VERSION ""

NS_ :

BS_:

BU_: ZD VCU TPMS RESERVED_FRAMES RCM RAC PCU PAS ESP DiagnosticTester CHG CDCM BMS ABS

BO_ 1091 VCU_Stored_SC_Errors: 8 VCU
 SG_ VCUStoredBeltWarningLightSC : 13|1@0+ (1,0) [0|1] "" Vector__XXX
 SG_ VCUStoredLowSOCSC : 0|1@0+ (1,0) [0|1] "" Vector__XXX
 SG_ VCUStoredRearSeatBuckle2LightSC : 26|1@0+ (1,0) [0|1] "" Vector__XXX
 SG_ VCUStoredReverseLightSC : 9|1@0+ (1,0) [0|1] "" Vector__XXX
 SG_ VCUStoredRadioMuteSC : 33|1@0+ (1,0) [0|1] "" Vector__XXX
 SG_ VCUStoredIllumOutputSC : 21|1@0+ (1,0) [0|1] "" Vector__XXX
 SG_ VCUStoredNeutralLightSC : 8|1@0+ (1,0) [0|1] "" Vector__XXX
 SG_ VCUStoredDriveEnableLightSC : 39|1@0+ (1,0) [0|1] "" Vector__XXX
 SG_ VCUStoredOvertempLightSC : 3|1@0+ (1,0) [0|1] "" Vector__XXX
 SG_ VCUStoredIndicationBarSupplySC : 18|1@0+ (1,0) [0|1] "" Vector__XXX
 SG_ VCUStoredPowerLimitLightSC : 5|1@0+ (1,0) [0|1] "" Vector__XXX
 SG_ VCUStoredTransceiverTXSC : 20|1@0+ (1,0) [0|1] "" Vector__XXX
 SG_ VCUStoredElHazardLightSC : 2|1@0+ (1,0) [0|1] "" Vector__XXX
 SG_ VCUStoredBrakeWarningLightSC : 38|1@0+ (1,0) [0|1] "" Vector__XXX
 SG_ VCUStoredEconomyGaugeSC : 36|1@0+ (1,0) [0|1] "" Vector__XXX
 SG_ VCUStoredTransceiverSupplySC : 32|1@0+ (1,0) [0|1] "" Vector__XXX
 SG_ VCUStoredDischargeRequestSC : 25|1@0+ (1,0) [0|1] "" Vector__XXX
 SG_ VCUStoredCrashLineSC : 17|1@0+ (1,0) [0|1] "" Vector__XXX
 SG_ VCUStoredABSWarningLightSC : 4|1@0+ (1,0) [0|1] "" Vector__XXX
 SG_ VCUStoredImmoLightSC : 19|1@0+ (1,0) [0|1] "" Vector__XXX
 SG_ VCUStoredDriveLightSC : 7|1@0+ (1,0) [0|1] "" Vector__XXX
 SG_ VCUStoredAuxBattLowLightSC : 11|1@0+ (1,0) [0|1] "" Vector__XXX
 SG_ VCUStoredChargeLightSC : 31|1@0+ (1,0) [0|1] "" Vector__XXX
 SG_ VCUStoredTPMSLightSC : 12|1@0+ (1,0) [0|1] "" Vector__XXX
 SG_ VCUStoredSpeedGaugeSC : 28|1@0+ (1,0) [0|1] "" Vector__XXX
 SG_ VCUStoredEconomyLightSC : 6|1@0+ (1,0) [0|1] "" Vector__XXX
 SG_ VCUStoredOnPlugLightSC : 30|1@0+ (1,0) [0|1] "" Vector__XXX
 SG_ VCUStoredChimeLineSC : 34|1@0+ (1,0) [0|1] "" Vector__XXX
 SG_ VCUStoredESPLightSC : 15|1@0+ (1,0) [0|1] "" Vector__XXX
 SG_ VCUStoredSOCGaugeSC : 37|1@0+ (1,0) [0|1] "" Vector__XXX
 SG_ VCUStoredMILLightSC : 1|1@0+ (1,0) [0|1] "" Vector__XXX
 SG_ VCUStoredParkLightSC : 10|1@0+ (1,0) [0|1] "" Vector__XXX
 SG_ VCUStoredAirbagLightSC : 29|1@0+ (1,0) [0|1] "" Vector__XXX
 SG_ VCUStoredIgnitionSpeedSC : 16|1@0+ (1,0) [0|1] "" Vector__XXX
 SG_ VCUStoredRearSeatBuckle1LightSC : 27|1@0+ (1,0) [0|1] "" Vector__XXX

BO_ 1092 VCU_Stored_OC_Errors: 8 VCU
 SG_ VCUStoredImmoLightOC : 19|1@0+ (1,0) [0|1] "" Vector__XXX
 SG_ VCUStoredReverseLightOC : 9|1@0+ (1,0) [0|1] "" Vector__XXX
 SG_ VCUStoredDischargeRequestOC : 25|1@0+ (1,0) [0|1] "" Vector__XXX
 SG_ VCUStoredPowerLimitLightOC : 5|1@0+ (1,0) [0|1] "" Vector__XXX
 SG_ VCUStoredRearSeatBuckle1LightOC : 27|1@0+ (1,0) [0|1] "" Vector__XXX
 SG_ VCUStoredTPMSLightOC : 12|1@0+ (1,0) [0|1] "" Vector__XXX
 SG_ VCUStoredOvertempLightOC : 3|1@0+ (1,0) [0|1] "" Vector__XXX
 SG_ VCUStoredSOCGaugeOC : 37|1@0+ (1,0) [0|1] "" Vector__XXX
 SG_ VCUStoredESPLightOC : 15|1@0+ (1,0) [0|1] "" Vector__XXX
 SG_ VCUStoredCrashLineOC : 17|1@0+ (1,0) [0|1] "" Vector__XXX
 SG_ VCUStoredIndicationBarSupplyOC : 18|1@0+ (1,0) [0|1] "" Vector__XXX
 SG_ VCUStoredEconomyLightOC : 6|1@0+ (1,0) [0|1] "" Vector__XXX
 SG_ VCUStoredAirbagLightOC : 29|1@0+ (1,0) [0|1] "" Vector__XXX
 SG_ VCUStoredEconomyGaugeOC : 36|1@0+ (1,0) [0|1] "" Vector__XXX
 SG_ VCUStoredTransceiverSupplyOC : 32|1@0+ (1,0) [0|1] "" Vector__XXX
 SG_ VCUStoredDriveLightOC : 7|1@0+ (1,0) [0|1] "" Vector__XXX
 SG_ VCUStoredAuxBattLowLightOC : 11|1@0+ (1,0) [0|1] "" Vector__XXX
 SG_ VCUStoredRearSeatBuckle2LightOC : 26|1@0+ (1,0) [0|1] "" Vector__XXX
 SG_ VCUStoredIgnitionSpeedOC : 16|1@0+ (1,0) [0|1] "" Vector__XXX
 SG_ VCUStoredMILLightOC : 1|1@0+ (1,0) [0|1] "" Vector__XXX
 SG_ VCUStoredChimeLineOC : 34|1@0+ (1,0) [0|1] "" Vector__XXX
 SG_ VCUStoredDriveEnableLightOC : 39|1@0+ (1,0) [0|1] "" Vector__XXX
 SG_ VCUStoredLowSOCOC : 0|1@0+ (1,0) [0|1] "" Vector__XXX
 SG_ VCUStoredElHazardLightOC : 2|1@0+ (1,0) [0|1] "" Vector__XXX
 SG_ VCUStoredBrakeWarningLightOC : 38|1@0+ (1,0) [0|1] "" Vector__XXX
 SG_ VCUStoredIllumOutputOC : 21|1@0+ (1,0) [0|1] "" Vector__XXX
 SG_ VCUStoredABSWarningLightOC : 4|1@0+ (1,0) [0|1] "" Vector__XXX
 SG_ VCUStoredTransceiverTXOC : 20|1@0+ (1,0) [0|1] "" Vector__XXX
 SG_ VCUStoredBeltWarningLightOC : 13|1@0+ (1,0) [0|1] "" Vector__XXX
 SG_ VCUStoredSpeedGaugeOC : 28|1@0+ (1,0) [0|1] "" Vector__XXX
 SG_ VCUStoredRadioMuteOC : 33|1@0+ (1,0) [0|1] "" Vector__XXX
 SG_ VCUStoredParkLightOC : 10|1@0+ (1,0) [0|1] "" Vector__XXX
 SG_ VCUStoredNeutralLightOC : 8|1@0+ (1,0) [0|1] "" Vector__XXX
 SG_ VCUStoredChargeLightOC : 31|1@0+ (1,0) [0|1] "" Vector__XXX
 SG_ VCUStoredOnPlugLightOC : 30|1@0+ (1,0) [0|1] "" Vector__XXX

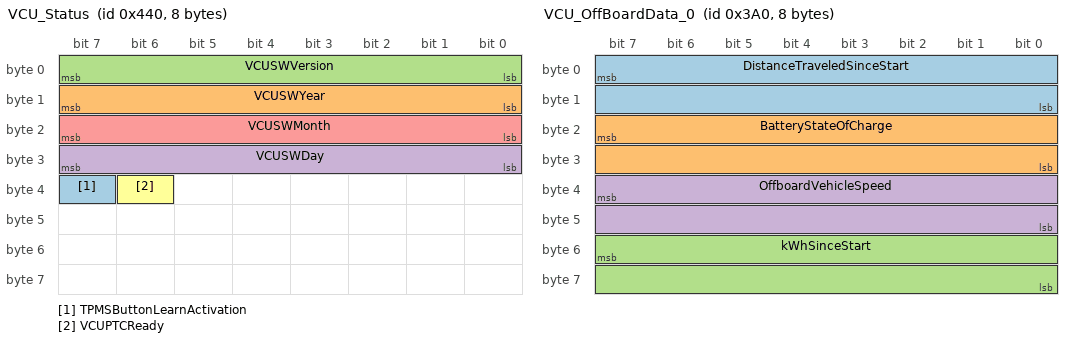
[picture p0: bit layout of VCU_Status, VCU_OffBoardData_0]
BO_ 1088 VCU_Status: 8 VCU
 SG_ TPMSButtonLearnActivation : 39|1@0+ (1,0) [0|1] "" Vector__XXX
 SG_ VCUSWYear : 15|8@0+ (1,0) [0|255] "" Vector__XXX
 SG_ VCUSWVersion : 7|8@0+ (1,0) [0|255] "" Vector__XXX
 SG_ VCUSWDay : 31|8@0+ (1,0) [0|255] "" Vector__XXX
 SG_ VCUSWMonth : 23|8@0+ (1,0) [0|255] "" Vector__XXX
 SG_ VCUPTCReady : 38|1@0+ (1,0) [0|1] "" Vector__XXX

BO_ 1089 VCU_Present_SC_Errors: 8 VCU
 SG_ VCUPresentMILLightSC : 1|1@0+ (1,0) [0|1] "" Vector__XXX
 SG_ VCUPresentImmoLightSC : 19|1@0+ (1,0) [0|1] "" Vector__XXX
 SG_ VCUPresentEconomyLightSC : 6|1@0+ (1,0) [0|1] "" Vector__XXX
 SG_ VCUPresentTransceiverSupplySC : 32|1@0+ (1,0) [0|1] "" Vector__XXX
 SG_ VCUPresentIgnitionSpeedSC : 16|1@0+ (1,0) [0|1] "" Vector__XXX
 SG_ VCUPresentChimeLineSC : 34|1@0+ (1,0) [0|1] "" Vector__XXX
 SG_ VCUPresentElHazardLightSC : 2|1@0+ (1,0) [0|1] "" Vector__XXX
 SG_ VCUPresentBrakeWarningLightSC : 38|1@0+ (1,0) [0|1] "" Vector__XXX
 SG_ VCUPresentRadioMuteSC : 33|1@0+ (1,0) [0|1] "" Vector__XXX
 SG_ VCUPresentSOCGaugeSC : 37|1@0+ (1,0) [0|1] "" Vector__XXX
 SG_ VCUPresentNeutralLightSC : 8|1@0+ (1,0) [0|1] "" Vector__XXX
 SG_ VCUPresentParkLightSC : 10|1@0+ (1,0) [0|1] "" Vector__XXX
 SG_ VCUPresentChargeLightSC : 31|1@0+ (1,0) [0|1] "" Vector__XXX
 SG_ VCUPresentEconomyGaugeSC : 36|1@0+ (1,0) [0|1] "" Vector__XXX
 SG_ VCUPresentCrashLineSC : 17|1@0+ (1,0) [0|1] "" Vector__XXX
 SG_ VCUPresentESPLightSC : 15|1@0+ (1,0) [0|1] "" Vector__XXX
 SG_ VCUPresentTransceiverTXSC : 20|1@0+ (1,0) [0|1] "" Vector__XXX
 SG_ VCUPresentReverseLightSC : 9|1@0+ (1,0) [0|1] "" Vector__XXX
 SG_ VCUPresentAirbagLightSC : 29|1@0+ (1,0) [0|1] "" Vector__XXX
 SG_ VCUPresentIndicationBarSupplySC : 18|1@0+ (1,0) [0|1] "" Vector__XXX
 SG_ VCUPresentDriveLightSC : 7|1@0+ (1,0) [0|1] "" Vector__XXX
 SG_ VCUPresentRearSeatBuckle1LightSC : 27|1@0+ (1,0) [0|1] "" Vector__XXX
 SG_ VCUPresentDischargeRequestSC : 25|1@0+ (1,0) [0|1] "" Vector__XXX
 SG_ VCUPresentAuxBattLowLightSC : 11|1@0+ (1,0) [0|1] "" Vector__XXX
 SG_ VCUPresentDriveEnableLightSC : 39|1@0+ (1,0) [0|1] "" Vector__XXX
 SG_ VCUPresentLowSOCSC : 0|1@0+ (1,0) [0|1] "" Vector__XXX
 SG_ VCUPresentBeltWarningLightSC : 13|1@0+ (1,0) [0|1] "" Vector__XXX
 SG_ VCUPresentSpeedGaugeSC : 28|1@0+ (1,0) [0|1] "" Vector__XXX
 SG_ VCUPresentABSWarningLightSC : 4|1@0+ (1,0) [0|1] "" Vector__XXX
 SG_ VCUPresentOvertempLightSC : 3|1@0+ (1,0) [0|1] "" Vector__XXX
 SG_ VCUPresentOnPlugLightSC : 30|1@0+ (1,0) [0|1] "" Vector__XXX
 SG_ VCUPresentIllumOutputSC : 21|1@0+ (1,0) [0|1] "" Vector__XXX
 SG_ VCUPresentPowerLimitLightSC : 5|1@0+ (1,0) [0|1] "" Vector__XXX
 SG_ VCUPresentTPMSLightSC : 12|1@0+ (1,0) [0|1] "" Vector__XXX
 SG_ VCUPresentRearSeatBuckle2LightSC : 26|1@0+ (1,0) [0|1] "" Vector__XXX

BO_ 1090 VCU_Present_OC_Errors: 8 VCU
 SG_ VCUPresentIndicationBarSupplyOC : 18|1@0+ (1,0) [0|1] "" Vector__XXX
 SG_ VCUPresentLowSOCOC : 0|1@0+ (1,0) [0|1] "" Vector__XXX
 SG_ VCUPresentOvertempLightOC : 3|1@0+ (1,0) [0|1] "" Vector__XXX
 SG_ VCUPresentEconomyLightOC : 6|1@0+ (1,0) [0|1] "" Vector__XXX
 SG_ VCUPresentParkLightOC : 10|1@0+ (1,0) [0|1] "" Vector__XXX
 SG_ VCUPresentRadioMuteOC : 33|1@0+ (1,0) [0|1] "" Vector__XXX
 SG_ VCUPresentElHazardLightOC : 2|1@0+ (1,0) [0|1] "" Vector__XXX
 SG_ VCUPresentBeltWarningLightOC : 13|1@0+ (1,0) [0|1] "" Vector__XXX
 SG_ VCUPresentDriveEnableLightOC : 39|1@0+ (1,0) [0|1] "" Vector__XXX
 SG_ VCUPresentImmoLightOC : 19|1@0+ (1,0) [0|1] "" Vector__XXX
 SG_ VCUPresentAirbagLightOC : 29|1@0+ (1,0) [0|1] "" Vector__XXX
 SG_ VCUPresentSOCGaugeOC : 37|1@0+ (1,0) [0|1] "" Vector__XXX
 SG_ VCUPresentSpeedGaugeOC : 28|1@0+ (1,0) [0|1] "" Vector__XXX
 SG_ VCUPresentRearSeatBuckle2LightOC : 26|1@0+ (1,0) [0|1] "" Vector__XXX
 SG_ VCUPresentReverseLightOC : 9|1@0+ (1,0) [0|1] "" Vector__XXX
 SG_ VCUPresentIllumOutputOC : 21|1@0+ (1,0) [0|1] "" Vector__XXX
 SG_ VCUPresentBrakeWarningLightOC : 38|1@0+ (1,0) [0|1] "" Vector__XXX
 SG_ VCUPresentTransceiverSupplyOC : 32|1@0+ (1,0) [0|1] "" Vector__XXX
 SG_ VCUPresentABSWarningLightOC : 4|1@0+ (1,0) [0|1] "" Vector__XXX
 SG_ VCUPresentTransceiverTXOC : 20|1@0+ (1,0) [0|1] "" Vector__XXX
 SG_ VCUPresentDriveLightOC : 7|1@0+ (1,0) [0|1] "" Vector__XXX
 SG_ VCUPresentPowerLimitLightOC : 5|1@0+ (1,0) [0|1] "" Vector__XXX
 SG_ VCUPresentCrashLineOC : 17|1@0+ (1,0) [0|1] "" Vector__XXX
 SG_ VCUPresentIgnitionSpeedOC : 16|1@0+ (1,0) [0|1] "" Vector__XXX
 SG_ VCUPresentAuxBattLowLightOC : 11|1@0+ (1,0) [0|1] "" Vector__XXX
 SG_ VCUPresentChargeLightOC : 31|1@0+ (1,0) [0|1] "" Vector__XXX
 SG_ VCUPresentOnPlugLightOC : 30|1@0+ (1,0) [0|1] "" Vector__XXX
 SG_ VCUPresentNeutralLightOC : 8|1@0+ (1,0) [0|1] "" Vector__XXX
 SG_ VCUPresentEconomyGaugeOC : 36|1@0+ (1,0) [0|1] "" Vector__XXX
 SG_ VCUPresentChimeLineOC : 34|1@0+ (1,0) [0|1] "" Vector__XXX
 SG_ VCUPresentRearSeatBuckle1LightOC : 27|1@0+ (1,0) [0|1] "" Vector__XXX
 SG_ VCUPresentESPLightOC : 15|1@0+ (1,0) [0|1] "" Vector__XXX
 SG_ VCUPresentTPMSLightOC : 12|1@0+ (1,0) [0|1] "" Vector__XXX
 SG_ VCUPresentDischargeRequestOC : 25|1@0+ (1,0) [0|1] "" Vector__XXX
 SG_ VCUPresentMILLightOC : 1|1@0+ (1,0) [0|1] "" Vector__XXX

BO_ 929 VCU_OffBoardData_1: 8 VCU
 SG_ WarningLightTemperatureActivated : 30|1@0+ (1,0) [0|1] "" Vector__XXX
 SG_ WarningLightAirbagActivated : 28|1@0+ (1,0) [0|1] "" Vector__XXX
 SG_ OnPlugBatteryTemperatureControl : 3|1@0+ (1,0) [0|1] "" Vector__XXX
 SG_ OnPlugPCUChargeEnabled : 15|1@0+ (1,0) [0|1] "" Vector__XXX
 SG_ KeyOnEPOBroken : 9|1@0+ (1,0) [0|1] "" Vector__XXX
 SG_ OnPlugFullChargeRequested : 14|1@0+ (1,0) [0|1] "" Vector__XXX
 SG_ WarningLightTPMSActivated : 20|1@0+ (1,0) [0|1] "" Vector__XXX
 SG_ KeyOnTractionEnabled : 13|1@0+ (1,0) [0|1] "" Vector__XXX
 SG_ WarningLightPowerLimitActivated : 19|1@0+ (1,0) [0|1] "" Vector__XXX
 SG_ KeyOnImmobilizerEnabled : 12|1@0+ (1,0) [0|1] "" Vector__XXX
 SG_ ExternalTemperature : 39|8@0- (0.5,0) [-64|63.5] "degC" Vector__XXX
 SG_ WarningLightESPActivated : 31|1@0+ (1,0) [0|1] "" Vector__XXX
 SG_ KeyOnGearPosition : 27|3@0+ (1,0) [0|7] "" Vector__XXX
 SG_ WarningLightMalfunctionActivated : 29|1@0+ (1,0) [0|1] "" Vector__XXX
 SG_ WarningLightBrakeActivated : 16|1@0+ (1,0) [0|1] "" Vector__XXX
 SG_ OnPlugEndOfCharge : 4|1@0+ (1,0) [0|1] "" Vector__XXX
 SG_ OnPlugBatteryChargeEnabled : 0|1@0+ (1,0) [0|1] "" Vector__XXX
 SG_ WarningLightABSActivated : 17|1@0+ (1,0) [0|1] "" Vector__XXX
 SG_ NominalBatteryCapacity : 47|16@0+ (0.1,0) [0|6553.5] "kWh" Vector__XXX
 SG_ WarningLightLowSOCActivated : 21|1@0+ (1,0) [0|1] "" Vector__XXX
 SG_ OnPlugCharging : 5|1@0+ (1,0) [0|1] "" Vector__XXX
 SG_ OnPlugBatteryEvaluation : 2|1@0+ (1,0) [0|1] "" Vector__XXX
 SG_ KeyOnCrashDetected : 10|1@0+ (1,0) [0|1] "" Vector__XXX
 SG_ KeyOnBatteryDischargeEnabled : 11|1@0+ (1,0) [0|1] "" Vector__XXX
 SG_ WarningLightElHazardActivated : 18|1@0+ (1,0) [0|1] "" Vector__XXX
 SG_ VehicleState : 7|2@0+ (1,0) [0|3] "" Vector__XXX
 SG_ OnPlugChargerEnabled : 1|1@0+ (1,0) [0|1] "" Vector__XXX

BO_ 928 VCU_OffBoardData_0: 8 VCU
 SG_ DistanceTraveledSinceStart : 7|16@0+ (0.1,0) [0|6553.5] "km" Vector__XXX
 SG_ BatteryStateOfCharge : 23|16@0+ (0.1,0) [0|6553.5] "%" Vector__XXX
 SG_ kWhSinceStart : 55|16@0+ (0.01,0) [0|655.35] "kWh" Vector__XXX
 SG_ OffboardVehicleSpeed : 39|16@0+ (0.1,0) [0|6553.5] "km/h" Vector__XXX

BO_ 592 VCU_Immo: 8 VCU
 SG_ MoreThanMaxError : 19|1@0+ (1,0) [0|1] ""  PCU
 SG_ ChallengeResponseActive : 1|1@0+ (1,0) [0|1] ""  PCU
 SG_ AntennaError : 17|1@0+ (1,0) [0|1] ""  PCU
 SG_ TransponderError : 16|1@0+ (1,0) [0|1] ""  PCU
 SG_ ChallengeMissingError : 27|1@0+ (1,0) [0|1] ""  PCU
 SG_ PartialKeyCodeError : 31|1@0+ (1,0) [0|1] ""  PCU
 SG_ RequestID : 2|1@0+ (1,0) [0|1] ""  PCU
 SG_ AntiscanError : 20|1@0+ (1,0) [0|1] ""  PCU
 SG_ MismatchError : 26|1@0+ (1,0) [0|1] ""  PCU
 SG_ LEDIndication : 7|3@0+ (1,0) [0|7] ""  PCU
 SG_ NoCommunicationError : 18|1@0+ (1,0) [0|1] ""  PCU
 SG_ KeyStatus : 4|2@0+ (1,0) [0|3] ""  PCU
 SG_ SecurityIDRefuseError : 25|1@0+ (1,0) [0|1] ""  PCU
 SG_ LessThanMinError : 28|1@0+ (1,0) [0|1] ""  PCU
 SG_ SecurityIDNotProgrammedError : 24|1@0+ (1,0) [0|1] ""  PCU
 SG_ SecurityIDMissingError : 29|1@0+ (1,0) [0|1] ""  PCU
 SG_ UnprogrammedError : 30|1@0+ (1,0) [0|1] ""  PCU
 SG_ NumberProgrammedKeys : 23|3@0+ (1,0) [0|7] "" Vector__XXX
 SG_ ChallengeResponse : 39|32@0+ (1,0) [0|4294967295] ""  PCU

BO_ 2001 VCU_Diagnostic: 8 VCU

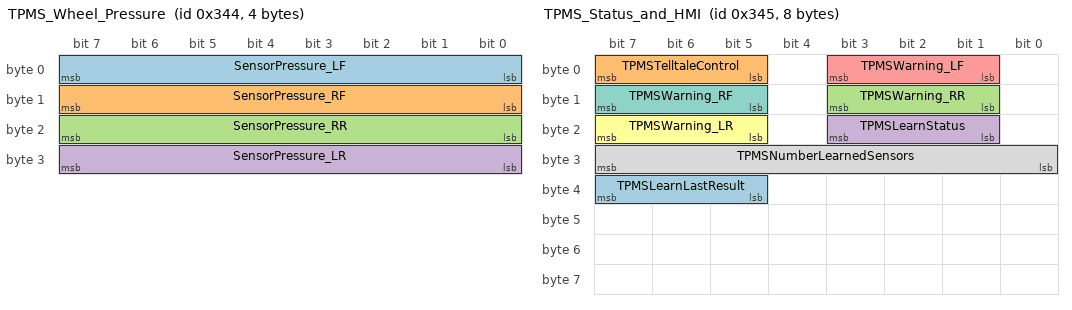
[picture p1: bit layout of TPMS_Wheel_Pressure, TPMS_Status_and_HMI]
BO_ 836 TPMS_Wheel_Pressure: 4 TPMS
 SG_ SensorPressure_LF : 7|8@0+ (0.025,0) [0|6.375] "bar" Vector__XXX
 SG_ SensorPressure_RF : 15|8@0+ (0.025,0) [0|6.375] "bar" Vector__XXX
 SG_ SensorPressure_RR : 23|8@0+ (0.025,0) [0|6.375] "bar" Vector__XXX
 SG_ SensorPressure_LR : 31|8@0+ (0.025,0) [0|6.375] "bar" Vector__XXX

BO_ 837 TPMS_Status_and_HMI: 8 TPMS
 SG_ TPMSLearnLastResult : 39|3@0+ (1,0) [0|7] "" Vector__XXX
 SG_ TPMSTelltaleControl : 7|3@0+ (1,0) [0|7] "" Vector__XXX
 SG_ TPMSWarning_RR : 11|3@0+ (1,0) [0|7] "" Vector__XXX
 SG_ TPMSLearnStatus : 19|3@0+ (1,0) [0|7] "" Vector__XXX
 SG_ TPMSWarning_LF : 3|3@0+ (1,0) [0|7] "" Vector__XXX
 SG_ TPMSWarning_LR : 23|3@0+ (1,0) [0|7] "" Vector__XXX
 SG_ TPMSWarning_RF : 15|3@0+ (1,0) [0|7] "" Vector__XXX
 SG_ TPMSNumberLearnedSensors : 31|8@0+ (1,0) [0|255] "" Vector__XXX

BO_ 1922 TPMS_Diagnostic: 8 TPMS

BO_ 838 TPMS_Debug: 8 TPMS

BO_ 1941 Reserver_104: 8 RESERVED_FRAMES

BO_ 1525 Reserved_99: 8 RESERVED_FRAMES

BO_ 1493 Reserved_98: 8 RESERVED_FRAMES

BO_ 1631 Reserved_97: 8 RESERVED_FRAMES

BO_ 1630 Reserved_96: 8 RESERVED_FRAMES

BO_ 1629 Reserved_95: 8 RESERVED_FRAMES

BO_ 1628 Reserved_94: 8 RESERVED_FRAMES

BO_ 1627 Reserved_93: 8 RESERVED_FRAMES

BO_ 1626 Reserved_92: 8 RESERVED_FRAMES

BO_ 1625 Reserved_91: 8 RESERVED_FRAMES

BO_ 1624 Reserved_90: 8 RESERVED_FRAMES

BO_ 1623 Reserved_89: 8 RESERVED_FRAMES

BO_ 1622 Reserved_88: 8 RESERVED_FRAMES

BO_ 1621 Reserved_87: 8 RESERVED_FRAMES

BO_ 1620 Reserved_86: 8 RESERVED_FRAMES

BO_ 1619 Reserved_85: 8 RESERVED_FRAMES

BO_ 1618 Reserved_84: 8 RESERVED_FRAMES

BO_ 1617 Reserved_83: 8 RESERVED_FRAMES

BO_ 1616 Reserved_82: 8 RESERVED_FRAMES

BO_ 1615 Reserved_81: 8 RESERVED_FRAMES

BO_ 1614 Reserved_80: 8 RESERVED_FRAMES

BO_ 645 Reserved_8: 8 RESERVED_FRAMES

BO_ 1613 Reserved_79: 8 RESERVED_FRAMES

BO_ 1612 Reserved_78: 8 RESERVED_FRAMES

BO_ 1611 Reserved_77: 8 RESERVED_FRAMES

BO_ 1610 Reserved_76: 8 RESERVED_FRAMES

BO_ 1609 Reserved_75: 8 RESERVED_FRAMES

BO_ 1608 Reserved_74: 8 ZD

BO_ 1607 Reserved_73: 8 RESERVED_FRAMES

BO_ 1606 Reserved_72: 8 BMS

BO_ 1605 Reserved_71: 8 RESERVED_FRAMES

BO_ 1604 Reserved_70: 8 BMS

BO_ 513 Reserved_7: 8 RESERVED_FRAMES

BO_ 1603 Reserved_69: 8 RESERVED_FRAMES

BO_ 1602 Reserved_68: 8 BMS

BO_ 1601 Reserved_67: 8 RESERVED_FRAMES

BO_ 1600 Reserved_66: 8 RESERVED_FRAMES

BO_ 1584 Reserved_65: 8 RESERVED_FRAMES

BO_ 831 Reserved_64: 8 RESERVED_FRAMES

BO_ 830 Reserved_63: 8 RESERVED_FRAMES

BO_ 829 Reserved_62: 8 RESERVED_FRAMES

BO_ 828 Reserved_61: 8 RESERVED_FRAMES

BO_ 827 Reserved_60: 8 RESERVED_FRAMES

BO_ 512 Reserved_6: 8 RESERVED_FRAMES

BO_ 826 Reserved_59: 8 RESERVED_FRAMES

BO_ 825 Reserved_58: 8 RESERVED_FRAMES

BO_ 824 Reserved_57: 8 RESERVED_FRAMES

BO_ 823 Reserved_56: 8 RESERVED_FRAMES

BO_ 822 Reserved_55: 8 RESERVED_FRAMES

BO_ 821 Reserved_54: 8 RESERVED_FRAMES

BO_ 820 Reserved_53: 8 RESERVED_FRAMES

BO_ 819 Reserved_52: 8 RESERVED_FRAMES

BO_ 818 Reserved_51: 8 RESERVED_FRAMES

BO_ 817 Reserved_50: 8 RESERVED_FRAMES

BO_ 1568 Reserved_5: 8 RESERVED_FRAMES

BO_ 816 Reserved_49: 8 RESERVED_FRAMES

BO_ 815 Reserved_48: 8 RESERVED_FRAMES

BO_ 814 Reserved_47: 8 RESERVED_FRAMES

BO_ 813 Reserved_46: 8 RESERVED_FRAMES

BO_ 812 Reserved_45: 8 RESERVED_FRAMES

BO_ 811 Reserved_44: 8 RESERVED_FRAMES

BO_ 810 Reserved_43: 8 RESERVED_FRAMES

BO_ 809 Reserved_42: 8 RESERVED_FRAMES

BO_ 808 Reserved_41: 8 RESERVED_FRAMES

BO_ 1892 Reserved_401: 8 RESERVED_FRAMES

BO_ 1888 Reserved_400: 8 RESERVED_FRAMES

BO_ 807 Reserved_40: 8 RESERVED_FRAMES

BO_ 1072 Reserved_4: 8 RESERVED_FRAMES

BO_ 1034 Reserved_399: 8 RESERVED_FRAMES

BO_ 1585 Reserved_398: 8 RESERVED_FRAMES

BO_ 1569 Reserved_397: 8 RESERVED_FRAMES

BO_ 857 Reserved_392: 8 RESERVED_FRAMES

BO_ 1567 Reserved_391: 8 RESERVED_FRAMES

BO_ 1566 Reserved_390: 8 RESERVED_FRAMES

BO_ 806 Reserved_39: 8 RESERVED_FRAMES

BO_ 1565 Reserved_389: 8 RESERVED_FRAMES

BO_ 1564 Reserved_388: 8 RESERVED_FRAMES

BO_ 1563 Reserved_387: 8 RESERVED_FRAMES

BO_ 1562 Reserved_386: 8 RESERVED_FRAMES

BO_ 1561 Reserved_385: 8 RESERVED_FRAMES

BO_ 1560 Reserved_384: 8 RESERVED_FRAMES

BO_ 1559 Reserved_383: 8 RESERVED_FRAMES

BO_ 1558 Reserved_382: 8 RESERVED_FRAMES

BO_ 1557 Reserved_381: 8 RESERVED_FRAMES

BO_ 1556 Reserved_380: 8 RESERVED_FRAMES

BO_ 805 Reserved_38: 8 RESERVED_FRAMES

BO_ 1555 Reserved_379: 8 RESERVED_FRAMES

BO_ 1554 Reserved_378: 8 RESERVED_FRAMES

BO_ 1553 Reserved_377: 8 RESERVED_FRAMES

BO_ 1552 Reserved_376: 8 RESERVED_FRAMES

BO_ 1551 Reserved_374: 8 RESERVED_FRAMES

BO_ 1550 Reserved_373: 8 RESERVED_FRAMES

BO_ 1549 Reserved_372: 8 RESERVED_FRAMES

BO_ 1548 Reserved_371: 8 RESERVED_FRAMES

BO_ 1547 Reserved_370: 8 RESERVED_FRAMES

BO_ 804 Reserved_37: 8 RESERVED_FRAMES

BO_ 1546 Reserved_369: 8 RESERVED_FRAMES

BO_ 1545 Reserved_368: 8 RESERVED_FRAMES

BO_ 1544 Reserved_367: 8 RESERVED_FRAMES

BO_ 1543 Reserved_366: 8 RESERVED_FRAMES

BO_ 1542 Reserved_365: 8 RESERVED_FRAMES

BO_ 1541 Reserved_364: 8 RESERVED_FRAMES

BO_ 1540 Reserved_363: 8 RESERVED_FRAMES

BO_ 1539 Reserved_362: 8 RESERVED_FRAMES

BO_ 1538 Reserved_361: 8 RESERVED_FRAMES

BO_ 1537 Reserved_360: 8 RESERVED_FRAMES

BO_ 803 Reserved_36: 8 RESERVED_FRAMES

BO_ 1536 Reserved_359: 8 RESERVED_FRAMES

BO_ 1535 Reserved_358: 8 RESERVED_FRAMES

BO_ 1534 Reserved_357: 8 RESERVED_FRAMES

BO_ 1533 Reserved_356: 8 RESERVED_FRAMES

BO_ 1532 Reserved_355: 8 RESERVED_FRAMES

BO_ 1531 Reserved_354: 8 RESERVED_FRAMES

BO_ 1530 Reserved_353: 8 RESERVED_FRAMES

BO_ 1529 Reserved_352: 8 RESERVED_FRAMES

BO_ 1528 Reserved_351: 8 RESERVED_FRAMES

BO_ 1527 Reserved_350: 8 RESERVED_FRAMES

BO_ 802 Reserved_35: 8 RESERVED_FRAMES

BO_ 1526 Reserved_349: 8 RESERVED_FRAMES

BO_ 1524 Reserved_348: 8 RESERVED_FRAMES

BO_ 1523 Reserved_347: 8 RESERVED_FRAMES

BO_ 1522 Reserved_346: 8 RESERVED_FRAMES

BO_ 1521 Reserved_345: 8 RESERVED_FRAMES

BO_ 1520 Reserved_344: 8 RESERVED_FRAMES

BO_ 1519 Reserved_343: 8 RESERVED_FRAMES

BO_ 1518 Reserved_342: 8 RESERVED_FRAMES

BO_ 1517 Reserved_341: 8 RESERVED_FRAMES

BO_ 1516 Reserved_340: 8 RESERVED_FRAMES

BO_ 801 Reserved_34: 8 RESERVED_FRAMES

BO_ 1515 Reserved_339: 8 RESERVED_FRAMES

BO_ 1514 Reserved_338: 8 RESERVED_FRAMES

BO_ 1513 Reserved_337: 8 RESERVED_FRAMES

BO_ 1512 Reserved_336: 8 RESERVED_FRAMES

BO_ 1511 Reserved_335: 8 RESERVED_FRAMES

BO_ 1510 Reserved_334: 8 RESERVED_FRAMES

BO_ 1509 Reserved_333: 8 RESERVED_FRAMES

BO_ 1508 Reserved_332: 8 RESERVED_FRAMES

BO_ 1507 Reserved_331: 8 RESERVED_FRAMES

BO_ 1506 Reserved_330: 8 RESERVED_FRAMES

BO_ 800 Reserved_33: 8 RESERVED_FRAMES

BO_ 1505 Reserved_329: 8 RESERVED_FRAMES

BO_ 1504 Reserved_328: 8 RESERVED_FRAMES

BO_ 1503 Reserved_327: 8 RESERVED_FRAMES

BO_ 1502 Reserved_326: 8 RESERVED_FRAMES

BO_ 1501 Reserved_325: 8 RESERVED_FRAMES

BO_ 1500 Reserved_324: 8 RESERVED_FRAMES

BO_ 1499 Reserved_323: 8 RESERVED_FRAMES

BO_ 1498 Reserved_322: 8 RESERVED_FRAMES

BO_ 1497 Reserved_321: 8 RESERVED_FRAMES

BO_ 1496 Reserved_320: 8 RESERVED_FRAMES

BO_ 799 Reserved_32: 8 RESERVED_FRAMES

BO_ 1495 Reserved_319: 8 RESERVED_FRAMES

BO_ 1494 Reserved_318: 8 RESERVED_FRAMES

BO_ 1492 Reserved_317: 8 RESERVED_FRAMES

BO_ 1491 Reserved_316: 8 RESERVED_FRAMES

BO_ 1490 Reserved_315: 8 RESERVED_FRAMES

BO_ 1489 Reserved_314: 8 RESERVED_FRAMES

BO_ 1488 Reserved_313: 8 RESERVED_FRAMES

BO_ 1487 Reserved_312: 8 RESERVED_FRAMES

BO_ 1486 Reserved_311: 8 RESERVED_FRAMES

BO_ 1485 Reserved_310: 8 RESERVED_FRAMES

BO_ 798 Reserved_31: 8 RESERVED_FRAMES

BO_ 1484 Reserved_309: 8 RESERVED_FRAMES

BO_ 1483 Reserved_308: 8 RESERVED_FRAMES

BO_ 1482 Reserved_307: 8 RESERVED_FRAMES

BO_ 1481 Reserved_306: 8 RESERVED_FRAMES

BO_ 1480 Reserved_305: 8 RESERVED_FRAMES

BO_ 1479 Reserved_304: 8 RESERVED_FRAMES

BO_ 1478 Reserved_303: 8 RESERVED_FRAMES

BO_ 1477 Reserved_302: 8 RESERVED_FRAMES

BO_ 1476 Reserved_301: 8 RESERVED_FRAMES

BO_ 1475 Reserved_300: 8 RESERVED_FRAMES

BO_ 797 Reserved_30: 8 RESERVED_FRAMES

BO_ 560 Reserved_3: 8 RESERVED_FRAMES

BO_ 1474 Reserved_299: 8 RESERVED_FRAMES

BO_ 1473 Reserved_298: 8 RESERVED_FRAMES

BO_ 1472 Reserved_297: 8 RESERVED_FRAMES

BO_ 1471 Reserved_296: 8 RESERVED_FRAMES

BO_ 1470 Reserved_295: 8 RESERVED_FRAMES

BO_ 1469 Reserved_294: 8 RESERVED_FRAMES

BO_ 1468 Reserved_293: 8 RESERVED_FRAMES

BO_ 1467 Reserved_292: 8 RESERVED_FRAMES

BO_ 1466 Reserved_291: 8 RESERVED_FRAMES

BO_ 1465 Reserved_290: 8 RESERVED_FRAMES

BO_ 796 Reserved_29: 8 RESERVED_FRAMES

BO_ 1464 Reserved_289: 8 RESERVED_FRAMES

BO_ 1463 Reserved_288: 8 RESERVED_FRAMES

BO_ 1462 Reserved_287: 8 RESERVED_FRAMES

BO_ 1461 Reserved_286: 8 RESERVED_FRAMES

BO_ 1460 Reserved_285: 8 RESERVED_FRAMES

BO_ 1459 Reserved_284: 8 RESERVED_FRAMES

BO_ 1458 Reserved_283: 8 RESERVED_FRAMES

BO_ 1457 Reserved_282: 8 RESERVED_FRAMES

BO_ 1456 Reserved_281: 8 RESERVED_FRAMES

BO_ 1455 Reserved_280: 8 RESERVED_FRAMES

BO_ 795 Reserved_28: 8 RESERVED_FRAMES

BO_ 1454 Reserved_279: 8 RESERVED_FRAMES

BO_ 1453 Reserved_278: 8 RESERVED_FRAMES

BO_ 1452 Reserved_277: 8 RESERVED_FRAMES

BO_ 1451 Reserved_276: 8 RESERVED_FRAMES

BO_ 1450 Reserved_275: 8 RESERVED_FRAMES

BO_ 1449 Reserved_274: 8 RESERVED_FRAMES

BO_ 1448 Reserved_273: 8 RESERVED_FRAMES

BO_ 1447 Reserved_272: 8 RESERVED_FRAMES

BO_ 1446 Reserved_271: 8 RESERVED_FRAMES

BO_ 1445 Reserved_270: 8 RESERVED_FRAMES

BO_ 794 Reserved_27: 8 RESERVED_FRAMES

BO_ 1444 Reserved_269: 8 RESERVED_FRAMES

BO_ 1443 Reserved_268: 8 RESERVED_FRAMES

BO_ 1442 Reserved_267: 8 RESERVED_FRAMES

BO_ 1441 Reserved_266: 8 RESERVED_FRAMES

BO_ 1440 Reserved_265: 8 RESERVED_FRAMES

BO_ 1439 Reserved_264: 8 RESERVED_FRAMES

BO_ 1438 Reserved_263: 8 RESERVED_FRAMES

BO_ 1437 Reserved_262: 8 RESERVED_FRAMES

BO_ 1436 Reserved_261: 8 RESERVED_FRAMES

BO_ 1435 Reserved_260: 8 RESERVED_FRAMES

BO_ 793 Reserved_26: 8 RESERVED_FRAMES

BO_ 1434 Reserved_259: 8 RESERVED_FRAMES

BO_ 1433 Reserved_258: 8 RESERVED_FRAMES

BO_ 1432 Reserved_257: 8 RESERVED_FRAMES

BO_ 1431 Reserved_256: 8 RESERVED_FRAMES

BO_ 1430 Reserved_255: 8 RESERVED_FRAMES

BO_ 1429 Reserved_254: 8 RESERVED_FRAMES

BO_ 1428 Reserved_253: 8 RESERVED_FRAMES

BO_ 1427 Reserved_252: 8 RESERVED_FRAMES

BO_ 1426 Reserved_251: 8 RESERVED_FRAMES

BO_ 1425 Reserved_250: 8 RESERVED_FRAMES

BO_ 792 Reserved_25: 8 RESERVED_FRAMES

BO_ 1424 Reserved_249: 8 RESERVED_FRAMES

BO_ 1423 Reserved_248: 8 RESERVED_FRAMES

BO_ 1422 Reserved_247: 8 RESERVED_FRAMES

BO_ 1421 Reserved_246: 8 RESERVED_FRAMES

BO_ 1420 Reserved_245: 8 RESERVED_FRAMES

BO_ 1419 Reserved_244: 8 RESERVED_FRAMES

BO_ 1418 Reserved_243: 8 RESERVED_FRAMES

BO_ 1417 Reserved_242: 8 RESERVED_FRAMES

BO_ 1416 Reserved_241: 8 RESERVED_FRAMES

BO_ 1415 Reserved_240: 8 RESERVED_FRAMES

BO_ 791 Reserved_24: 8 RESERVED_FRAMES

BO_ 1414 Reserved_239: 8 RESERVED_FRAMES

BO_ 1413 Reserved_238: 8 RESERVED_FRAMES

BO_ 1412 Reserved_237: 8 RESERVED_FRAMES

BO_ 1411 Reserved_236: 8 RESERVED_FRAMES

BO_ 1410 Reserved_235: 8 RESERVED_FRAMES

BO_ 1409 Reserved_234: 8 RESERVED_FRAMES

BO_ 1408 Reserved_233: 8 RESERVED_FRAMES

BO_ 1407 Reserved_232: 8 RESERVED_FRAMES

BO_ 1406 Reserved_231: 8 RESERVED_FRAMES

BO_ 1405 Reserved_230: 8 RESERVED_FRAMES

BO_ 790 Reserved_23: 8 RESERVED_FRAMES

BO_ 1404 Reserved_229: 8 RESERVED_FRAMES

BO_ 1403 Reserved_228: 8 RESERVED_FRAMES

BO_ 1402 Reserved_227: 8 RESERVED_FRAMES

BO_ 1401 Reserved_226: 8 RESERVED_FRAMES

BO_ 1400 Reserved_225: 8 RESERVED_FRAMES

BO_ 1399 Reserved_224: 8 RESERVED_FRAMES

BO_ 1398 Reserved_223: 8 RESERVED_FRAMES

BO_ 1397 Reserved_222: 8 RESERVED_FRAMES

BO_ 1396 Reserved_221: 8 RESERVED_FRAMES

BO_ 1395 Reserved_220: 8 RESERVED_FRAMES

BO_ 789 Reserved_22: 8 RESERVED_FRAMES

BO_ 1394 Reserved_219: 8 RESERVED_FRAMES

BO_ 1393 Reserved_218: 8 RESERVED_FRAMES

BO_ 1392 Reserved_217: 8 RESERVED_FRAMES

BO_ 1391 Reserved_216: 8 RESERVED_FRAMES

BO_ 1390 Reserved_215: 8 RESERVED_FRAMES

BO_ 1389 Reserved_214: 8 RESERVED_FRAMES

BO_ 1388 Reserved_213: 8 RESERVED_FRAMES

BO_ 1387 Reserved_212: 8 RESERVED_FRAMES

BO_ 1386 Reserved_211: 8 RESERVED_FRAMES

BO_ 1385 Reserved_210: 8 RESERVED_FRAMES

BO_ 788 Reserved_21: 8 RESERVED_FRAMES

BO_ 1384 Reserved_209: 8 RESERVED_FRAMES

BO_ 1383 Reserved_208: 8 RESERVED_FRAMES

BO_ 1382 Reserved_207: 8 RESERVED_FRAMES

BO_ 1381 Reserved_206: 8 RESERVED_FRAMES

BO_ 1380 Reserved_205: 8 RESERVED_FRAMES

BO_ 1379 Reserved_204: 8 RESERVED_FRAMES

BO_ 1378 Reserved_203: 8 RESERVED_FRAMES

BO_ 1377 Reserved_202: 8 RESERVED_FRAMES

BO_ 1376 Reserved_201: 8 RESERVED_FRAMES

BO_ 1375 Reserved_200: 8 RESERVED_FRAMES

BO_ 787 Reserved_20: 8 RESERVED_FRAMES

BO_ 144 Reserved_2: 8 RESERVED_FRAMES

BO_ 1374 Reserved_199: 8 RESERVED_FRAMES

BO_ 1373 Reserved_198: 8 RESERVED_FRAMES

BO_ 1372 Reserved_197: 8 RESERVED_FRAMES

BO_ 1371 Reserved_196: 8 RESERVED_FRAMES

BO_ 1370 Reserved_195: 8 RESERVED_FRAMES

BO_ 1369 Reserved_194: 8 RESERVED_FRAMES

BO_ 1368 Reserved_193: 8 RESERVED_FRAMES

BO_ 1367 Reserved_192: 8 RESERVED_FRAMES

BO_ 1366 Reserved_191: 8 RESERVED_FRAMES

BO_ 1365 Reserved_190: 8 RESERVED_FRAMES

BO_ 786 Reserved_19: 8 RESERVED_FRAMES

BO_ 1364 Reserved_189: 8 RESERVED_FRAMES

BO_ 1363 Reserved_188: 8 RESERVED_FRAMES

BO_ 1362 Reserved_187: 8 RESERVED_FRAMES

BO_ 1361 Reserved_186: 8 RESERVED_FRAMES

BO_ 1360 Reserved_185: 8 RESERVED_FRAMES

BO_ 1359 Reserved_184: 8 RESERVED_FRAMES

BO_ 1358 Reserved_183: 8 RESERVED_FRAMES

BO_ 1357 Reserved_182: 8 RESERVED_FRAMES

BO_ 1356 Reserved_181: 8 RESERVED_FRAMES

BO_ 1355 Reserved_180: 8 RESERVED_FRAMES

BO_ 1354 Reserved_179: 8 RESERVED_FRAMES

BO_ 1353 Reserved_178: 8 RESERVED_FRAMES

BO_ 1352 Reserved_177: 8 RESERVED_FRAMES

BO_ 1351 Reserved_176: 8 RESERVED_FRAMES

BO_ 1350 Reserved_175: 8 RESERVED_FRAMES

BO_ 1349 Reserved_174: 8 RESERVED_FRAMES

BO_ 1348 Reserved_173: 8 RESERVED_FRAMES

BO_ 1347 Reserved_172: 8 RESERVED_FRAMES

BO_ 1346 Reserved_171: 8 RESERVED_FRAMES

BO_ 1345 Reserved_170: 8 RESERVED_FRAMES

BO_ 1344 Reserved_169: 8 RESERVED_FRAMES

BO_ 1343 Reserved_168: 8 RESERVED_FRAMES

BO_ 1342 Reserved_167: 8 RESERVED_FRAMES

BO_ 1341 Reserved_166: 8 RESERVED_FRAMES

BO_ 1340 Reserved_165: 8 RESERVED_FRAMES

BO_ 1339 Reserved_164: 8 RESERVED_FRAMES

BO_ 1338 Reserved_163: 8 RESERVED_FRAMES

BO_ 1337 Reserved_162: 8 RESERVED_FRAMES

BO_ 1336 Reserved_161: 8 RESERVED_FRAMES

BO_ 1335 Reserved_160: 8 RESERVED_FRAMES

BO_ 781 Reserved_16: 8 RESERVED_FRAMES

BO_ 1334 Reserved_159: 8 RESERVED_FRAMES

BO_ 1333 Reserved_158: 8 RESERVED_FRAMES

BO_ 1332 Reserved_157: 8 RESERVED_FRAMES

BO_ 1331 Reserved_156: 8 RESERVED_FRAMES

BO_ 1330 Reserved_155: 8 RESERVED_FRAMES

BO_ 1329 Reserved_154: 8 RESERVED_FRAMES

BO_ 1328 Reserved_153: 8 RESERVED_FRAMES

BO_ 1327 Reserved_152: 8 RESERVED_FRAMES

BO_ 1326 Reserved_151: 8 RESERVED_FRAMES

BO_ 1325 Reserved_150: 8 RESERVED_FRAMES

BO_ 780 Reserved_15: 8 RESERVED_FRAMES

BO_ 1324 Reserved_149: 8 RESERVED_FRAMES

CM_ "Main CAN in vehicle, connected to diagnostic connector.

Rules of engagement:
-Nodes are not allowed to transmit if frames/signals not assigned to them.
-If empty space within frame, put 0.";
CM_ BU_ ZD "Zebra Battery Display.";
CM_ BU_ TPMS "Tire Pressure Monitoring System";
CM_ BU_ RESERVED_FRAMES "Virtual or hypothetical sender of the reserved frames. It is included as a node to be able to export the frames into the XML";
CM_ BU_ RCM "Restrains Control Module (Airbag and belt pretense control)";
CM_ BU_ RAC "Remote Acquisition Unit(Telematics)";
CM_ BU_ PCU "Power Conversion Unit and Motor Control";
CM_ BU_ PAS "Electro Hydraulic Power Assisted Steering";
CM_ BU_ ESP "Eslectronic Stability Process";
CM_ BU_ DiagnosticTester "Diagnostic tool. Included to reserve IDs ";
CM_ BU_ CHG "Eltek Charger";
CM_ BU_ CDCM "Climate Control Module";
CM_ BU_ BMS "Battery Management System";
CM_ BU_ ABS "Braking Control Module";
CM_ BO_ 1091 "Period of transmission if node active: 200ms";
CM_ BO_ 1092 "Period of transmission if node active: 200ms";
CM_ BO_ 1088 "Period of transmission if node active: 200ms";
CM_ BO_ 1089 "Period of transmission if node active: 200ms";
CM_ BO_ 1090 "Period of transmission if node active: 200ms";
CM_ BO_ 929 "Period of transmission if node active: 500ms";
CM_ BO_ 928 "Period of transmission if node active: 500ms";
CM_ BO_ 592 "Period of transmission if node active: 100 ms";
CM_ BO_ 2001 "Diagnostic Response from VCU";
CM_ BO_ 836 "Period of transmission if node active: 200ms";
CM_ SG_ 836 SensorPressure_LF "0xFF represents Signal Not Available";
CM_ SG_ 836 SensorPressure_RF "0xFF represents Signal Not Available";
CM_ SG_ 836 SensorPressure_RR "0xFF represents Signal Not Available";
CM_ SG_ 836 SensorPressure_LR "0xFF represents Signal Not Available";
CM_ BO_ 837 "Period of transmission if node active: 200ms";
CM_ BO_ 1922 "Diagnostic Response from TPMS";
CM_ BO_ 838 "Reserved for TPMS debug purposes";
CM_ BO_ 1941 "PAS may react to this frame. DO NOT TRANSMIT AT ANY MOMENT";
CM_ BO_ 1525 "Reserved for PAS CCP protocol. DO NOT TRANSMIT AT ANY MOMENT";
CM_ BO_ 1493 "Reserved for PAS CCP protocol. DO NOT TRANSMIT AT ANY MOMENT";
CM_ BO_ 1631 "Reserved for Zebra battery display communication";
CM_ BO_ 1630 "Reserved for Zebra battery display communication";
CM_ BO_ 1629 "Reserved for Zebra battery display communication";
CM_ BO_ 1628 "Reserved for Zebra battery display communication";
CM_ BO_ 1627 "Reserved for Zebra battery display communication";
CM_ BO_ 1626 "Reserved for Zebra battery display communication";
CM_ BO_ 1625 "Reserved for Zebra battery display communication";
CM_ BO_ 1624 "Reserved for Zebra battery display communication";
CM_ BO_ 1623 "Reserved for Zebra battery display communication";
CM_ BO_ 1622 "Reserved for Zebra battery display communication";
CM_ BO_ 1621 "Reserved for Zebra battery display communication";
CM_ BO_ 1620 "Reserved for Zebra battery display communication";
CM_ BO_ 1619 "Reserved for Zebra battery display communication";
CM_ BO_ 1618 "Reserved for Zebra battery display communication";
CM_ BO_ 1617 "Reserved for Zebra battery display communication";
CM_ BO_ 1616 "Reserved for Zebra battery display communication";
CM_ BO_ 1615 "Reserved for Zebra battery display communication";
CM_ BO_ 1614 "Reserved for Zebra battery display communication";
CM_ BO_ 645 "RCM will react to this frame. DO NOT TRANSMIT AT ANY MOMENT";
CM_ BO_ 1613 "Reserved for Zebra battery display communication";
CM_ BO_ 1612 "Reserved for Zebra battery display communication";
CM_ BO_ 1611 "Reserved for Zebra battery display communication";
CM_ BO_ 1610 "Reserved for Zebra battery display communication";
CM_ BO_ 1609 "Reserved for Zebra battery display communication";
CM_ BO_ 1608 "Sent only by Zebra Display. Reserved for ZD comunication.";
CM_ BO_ 1607 "Reserved for Zebra battery display communication";
CM_ BO_ 1606 "Sent only by Zebra BMS. Reserved for ZD comunication.";
CM_ BO_ 1605 "Reserved for Zebra battery display communication";
CM_ BO_ 1604 "Sent only by Zebra BMS. Reserved for ZD comunication.";
CM_ BO_ 513 "RCM will react to this frame. DO NOT TRANSMIT AT ANY MOMENT
A different version of ABS might use this frame. Do not use if possible.
";
CM_ BO_ 1603 "Reserved for Zebra battery display communication";
CM_ BO_ 1602 "Sent only by Zebra BMS. Reserved for ZD comunication.";
CM_ BO_ 1601 "Reserved for Zebra battery display communication";
CM_ BO_ 1600 "Reserved for Zebra battery display communication";
CM_ BO_ 1584 "ABS unit will react to this frame. DO NOT TRANSMIT AT ANY MOMENT";
CM_ BO_ 831 "Reserved for Fuel Cell project. Do not use";
CM_ BO_ 830 "Reserved for Fuel Cell project. Do not use";
CM_ BO_ 829 "Reserved for Fuel Cell project. Do not use";
CM_ BO_ 828 "Reserved for Fuel Cell project. Do not use";
CM_ BO_ 827 "Reserved for Fuel Cell project. Do not use";
CM_ BO_ 512 "Zebra BMS will react to this frame. DO NOT TRANSMIT AT ANY MOMENT
A different version of ABS might use this frame. Do not use if possible.
";
CM_ BO_ 826 "Reserved for Fuel Cell project. Do not use";
CM_ BO_ 825 "Reserved for Fuel Cell project. Do not use";
CM_ BO_ 824 "Reserved for Fuel Cell project. Do not use";
CM_ BO_ 823 "Reserved for Fuel Cell project. Do not use";
CM_ BO_ 822 "Reserved for Fuel Cell project. Do not use";
CM_ BO_ 821 "Reserved for Fuel Cell project. Do not use";
CM_ BO_ 820 "Reserved for Fuel Cell project. Do not use";
CM_ BO_ 819 "Reserved for Fuel Cell project. Do not use";
CM_ BO_ 818 "Reserved for Fuel Cell project. Do not use";
CM_ BO_ 817 "Reserved for Fuel Cell project. Do not use";
CM_ BO_ 1568 "A different version of ABS might use this frame. Do not use if possible.";
CM_ BO_ 816 "Reserved for Fuel Cell project. Do not use";
CM_ BO_ 815 "Reserved for Fuel Cell project. Do not use";
CM_ BO_ 814 "Reserved for Fuel Cell project. Do not use";
CM_ BO_ 813 "Reserved for Fuel Cell project. Do not use";
CM_ BO_ 812 "Reserved for Fuel Cell project. Do not use";
CM_ BO_ 811 "Reserved for Fuel Cell project. Do not use";
CM_ BO_ 810 "Reserved for Fuel Cell project. Do not use";
CM_ BO_ 809 "Reserved for Fuel Cell project. Do not use";
CM_ BO_ 808 "Reserved for Fuel Cell project. Do not use";
CM_ BO_ 1892 "Reserved for CHG download.";
CM_ BO_ 1888 "Reserved for CHG download.";
CM_ BO_ 807 "Reserved for Fuel Cell project. Do not use";
CM_ BO_ 1072 "A different version of ABS might use this frame. Do not use if possible.";
CM_ BO_ 1034 "Previously (7.x) used for CDCM indication of Airbag Warning Lamp and Crash signal to the GEM. No longer used in 8.x

Reaserved";
CM_ BO_ 1585 "Reserved for ESP project. Do not use";
CM_ BO_ 1569 "Reserved for ESP project. Do not use";
CM_ BO_ 857 "Reserved for PCU";
CM_ BO_ 1567 "Reserved for Enerdel BMS";
CM_ BO_ 1566 "Reserved for Enerdel BMS";
CM_ BO_ 806 "Reserved for Fuel Cell project. Do not use";
CM_ BO_ 1565 "Reserved for Enerdel BMS";
CM_ BO_ 1564 "Reserved for Enerdel BMS";
CM_ BO_ 1563 "Reserved for Enerdel BMS";
CM_ BO_ 1562 "Reserved for Enerdel BMS";
CM_ BO_ 1561 "Reserved for Enerdel BMS";
CM_ BO_ 1560 "Reserved for Enerdel BMS";
CM_ BO_ 1559 "Reserved for Enerdel BMS";
CM_ BO_ 1558 "Reserved for Enerdel BMS";
CM_ BO_ 1557 "Reserved for Enerdel BMS";
CM_ BO_ 1556 "Reserved for Enerdel BMS";
CM_ BO_ 805 "Reserved for Fuel Cell project. Do not use";
CM_ BO_ 1555 "Reserved for Enerdel BMS";
CM_ BO_ 1554 "Reserved for Enerdel BMS";
CM_ BO_ 1553 "Reserved for Enerdel BMS";
CM_ BO_ 1552 "Reserved for Enerdel BMS";
CM_ BO_ 1551 "Reserved for A123 BMS";
CM_ BO_ 1550 "Reserved for A123 BMS";
CM_ BO_ 1549 "Reserved for A123 BMS";
CM_ BO_ 1548 "Reserved for A123 BMS";
CM_ BO_ 1547 "Reserved for A123 BMS";
CM_ BO_ 804 "Reserved for Fuel Cell project. Do not use";
CM_ BO_ 1546 "Reserved for A123 BMS";
CM_ BO_ 1545 "Reserved for A123 BMS";
CM_ BO_ 1544 "Reserved for A123 BMS";
CM_ BO_ 1543 "Reserved for A123 BMS";
CM_ BO_ 1542 "Reserved for A123 BMS";
CM_ BO_ 1541 "Reserved for A123 BMS";
CM_ BO_ 1540 "Reserved for A123 BMS";
CM_ BO_ 1539 "Reserved for A123 BMS";
CM_ BO_ 1538 "Reserved for A123 BMS";
CM_ BO_ 1537 "Reserved for A123 BMS";
CM_ BO_ 803 "Reserved for Fuel Cell project. Do not use";
CM_ BO_ 1536 "Reserved for A123 BMS. Usage and content must be approved by Think.";
CM_ BO_ 1535 "Reserved for Zebra BMI. Do not use if possible";
CM_ BO_ 1534 "Reserved for Zebra BMI. Do not use if possible";
CM_ BO_ 1533 "Reserved for Zebra BMI. Do not use if possible";
CM_ BO_ 1532 "Reserved for Zebra BMI. Do not use if possible";
CM_ BO_ 1531 "Reserved for Zebra BMI. Do not use if possible";
CM_ BO_ 1530 "Reserved for Zebra BMI. Do not use if possible";
CM_ BO_ 1529 "Reserved for Zebra BMI. Do not use if possible";
CM_ BO_ 1528 "Reserved for Zebra BMI. Do not use if possible";
CM_ BO_ 1527 "Reserved for Zebra BMI. Do not use if possible";
CM_ BO_ 802 "Reserved for Fuel Cell project. Do not use";
CM_ BO_ 1526 "Reserved for Zebra BMI. Do not use if possible";
CM_ BO_ 1524 "Reserved for Zebra BMI. Do not use if possible";
CM_ BO_ 1523 "Reserved for Zebra BMI. Do not use if possible";
CM_ BO_ 1522 "Reserved for Zebra BMI. Do not use if possible";
CM_ BO_ 1521 "Reserved for Zebra BMI. Do not use if possible";
CM_ BO_ 1520 "Reserved for Zebra BMI. Do not use if possible";
CM_ BO_ 1519 "Reserved for Zebra BMI. Do not use if possible";
CM_ BO_ 1518 "Reserved for Zebra BMI. Do not use if possible";
CM_ BO_ 1517 "Reserved for Zebra BMI. Do not use if possible";
CM_ BO_ 1516 "Reserved for Zebra BMI. Do not use if possible";
CM_ BO_ 801 "Reserved for Fuel Cell project. Do not use";
CM_ BO_ 1515 "Reserved for Zebra BMI. Do not use if possible";
CM_ BO_ 1514 "Reserved for Zebra BMI. Do not use if possible";
CM_ BO_ 1513 "Reserved for Zebra BMI. Do not use if possible";
CM_ BO_ 1512 "Reserved for Zebra BMI. Do not use if possible";
CM_ BO_ 1511 "Reserved for Zebra BMI. Do not use if possible";
CM_ BO_ 1510 "Reserved for Zebra BMI. Do not use if possible";
CM_ BO_ 1509 "Reserved for Zebra BMI. Do not use if possible";
CM_ BO_ 1508 "Reserved for Zebra BMI. Do not use if possible";
CM_ BO_ 1507 "Reserved for Zebra BMI. Do not use if possible";
CM_ BO_ 1506 "Reserved for Zebra BMI. Do not use if possible";
CM_ BO_ 800 "Reserved for Fuel Cell project. Do not use";
CM_ BO_ 1505 "Reserved for Zebra BMI. Do not use if possible";
CM_ BO_ 1504 "Reserved for Zebra BMI. Do not use if possible";
CM_ BO_ 1503 "Reserved for Zebra BMI. Do not use if possible";
CM_ BO_ 1502 "Reserved for Zebra BMI. Do not use if possible";
CM_ BO_ 1501 "Reserved for Zebra BMI. Do not use if possible";
CM_ BO_ 1500 "Reserved for Zebra BMI. Do not use if possible";
CM_ BO_ 1499 "Reserved for Zebra BMI. Do not use if possible";
CM_ BO_ 1498 "Reserved for Zebra BMI. Do not use if possible";
CM_ BO_ 1497 "Reserved for Zebra BMI. Do not use if possible";
CM_ BO_ 1496 "Reserved for Zebra BMI. Do not use if possible";
CM_ BO_ 799 "Reserved for PCU comunication with Zebra BMI. Do not use if possible";
CM_ BO_ 1495 "Reserved for Zebra BMI. Do not use if possible";
CM_ BO_ 1494 "Reserved for Zebra BMI. Do not use if possible";
CM_ BO_ 1492 "Reserved for Zebra BMI. Do not use if possible";
CM_ BO_ 1491 "Reserved for Zebra BMI. Do not use if possible";
CM_ BO_ 1490 "Reserved for Zebra BMI. Do not use if possible";
CM_ BO_ 1489 "Reserved for Zebra BMI. Do not use if possible";
CM_ BO_ 1488 "Reserved for Zebra BMI. Do not use if possible";
CM_ BO_ 1487 "Reserved for Zebra BMI. Do not use if possible";
CM_ BO_ 1486 "Reserved for Zebra BMI. Do not use if possible";
CM_ BO_ 1485 "Reserved for Zebra BMI. Do not use if possible";
CM_ BO_ 798 "Reserved for PCU comunication with Zebra BMI. Do not use if possible";
CM_ BO_ 1484 "Reserved for Zebra BMI. Do not use if possible";
CM_ BO_ 1483 "Reserved for Zebra BMI. Do not use if possible";
CM_ BO_ 1482 "Reserved for Zebra BMI. Do not use if possible";
CM_ BO_ 1481 "Reserved for Zebra BMI. Do not use if possible";
CM_ BO_ 1480 "Reserved for Zebra BMI. Do not use if possible";
CM_ BO_ 1479 "Reserved for Zebra BMI. Do not use if possible";
CM_ BO_ 1478 "Reserved for Zebra BMI. Do not use if possible";
CM_ BO_ 1477 "Reserved for Zebra BMI. Do not use if possible";
CM_ BO_ 1476 "Reserved for Zebra BMI. Do not use if possible";
CM_ BO_ 1475 "Reserved for Zebra BMI. Do not use if possible";
CM_ BO_ 797 "Reserved for PCU comunication with Zebra BMI. Do not use if possible";
CM_ BO_ 560 "A different version of ABS might use this frame. Do not use if possible.";
CM_ BO_ 1474 "Reserved for Zebra BMI. Do not use if possible";
CM_ BO_ 1473 "Reserved for Zebra BMI. Do not use if possible";
CM_ BO_ 1472 "Reserved for Zebra BMI. Do not use if possible";
CM_ BO_ 1471 "Reserved for Zebra BMI. Do not use if possible";
CM_ BO_ 1470 "Reserved for Zebra BMI. Do not use if possible";
CM_ BO_ 1469 "Reserved for Zebra BMI. Do not use if possible";
CM_ BO_ 1468 "Reserved for Zebra BMI. Do not use if possible";
CM_ BO_ 1467 "Reserved for Zebra BMI. Do not use if possible";
CM_ BO_ 1466 "Reserved for Zebra BMI. Do not use if possible";
CM_ BO_ 1465 "Reserved for Zebra BMI. Do not use if possible";
CM_ BO_ 796 "Reserved for PCU comunication with Zebra BMI. Do not use if possible";
CM_ BO_ 1464 "Reserved for Zebra BMI. Do not use if possible";
CM_ BO_ 1463 "Reserved for Zebra BMI. Do not use if possible";
CM_ BO_ 1462 "Reserved for Zebra BMI. Do not use if possible";
CM_ BO_ 1461 "Reserved for Zebra BMI. Do not use if possible";
CM_ BO_ 1460 "Reserved for Zebra BMI. Do not use if possible";
CM_ BO_ 1459 "Reserved for Zebra BMI. Do not use if possible";
CM_ BO_ 1458 "Reserved for Zebra BMI. Do not use if possible";
CM_ BO_ 1457 "Reserved for Zebra BMI. Do not use if possible";
CM_ BO_ 1456 "Reserved for Zebra BMI. Do not use if possible";
CM_ BO_ 1455 "Reserved for Zebra BMI. Do not use if possible";
CM_ BO_ 795 "Reserved for PCU comunication with Zebra BMI. Do not use if possible";
CM_ BO_ 1454 "Reserved for Zebra BMI. Do not use if possible";
CM_ BO_ 1453 "Reserved for Zebra BMI. Do not use if possible";
CM_ BO_ 1452 "Reserved for Zebra BMI. Do not use if possible";
CM_ BO_ 1451 "Reserved for Zebra BMI. Do not use if possible";
CM_ BO_ 1450 "Reserved for Zebra BMI. Do not use if possible";
CM_ BO_ 1449 "Reserved for Zebra BMI. Do not use if possible";
CM_ BO_ 1448 "Reserved for Zebra BMI. Do not use if possible";
CM_ BO_ 1447 "Reserved for Zebra BMI. Do not use if possible";
CM_ BO_ 1446 "Reserved for Zebra BMI. Do not use if possible";
CM_ BO_ 1445 "Reserved for Zebra BMI. Do not use if possible";
CM_ BO_ 794 "Reserved for PCU comunication with Zebra BMI. Do not use if possible";
CM_ BO_ 1444 "Reserved for Zebra BMI. Do not use if possible";
CM_ BO_ 1443 "Reserved for Zebra BMI. Do not use if possible";
CM_ BO_ 1442 "Reserved for Zebra BMI. Do not use if possible";
CM_ BO_ 1441 "Reserved for Zebra BMI. Do not use if possible";
CM_ BO_ 1440 "Reserved for Zebra BMI. Do not use if possible";
CM_ BO_ 1439 "Reserved for Zebra BMI. Do not use if possible";
CM_ BO_ 1438 "Reserved for Zebra BMI. Do not use if possible";
CM_ BO_ 1437 "Reserved for Zebra BMI. Do not use if possible";
CM_ BO_ 1436 "Reserved for Zebra BMI. Do not use if possible";
CM_ BO_ 1435 "Reserved for Zebra BMI. Do not use if possible";
CM_ BO_ 793 "Reserved for PCU comunication with Zebra BMI. Do not use if possible";
CM_ BO_ 1434 "Reserved for Zebra BMI. Do not use if possible";
CM_ BO_ 1433 "Reserved for Zebra BMI. Do not use if possible";
CM_ BO_ 1432 "Reserved for Zebra BMI. Do not use if possible";
CM_ BO_ 1431 "Reserved for Zebra BMI. Do not use if possible";
CM_ BO_ 1430 "Reserved for Zebra BMI. Do not use if possible";
CM_ BO_ 1429 "Reserved for Zebra BMI. Do not use if possible";
CM_ BO_ 1428 "Reserved for Zebra BMI. Do not use if possible";
CM_ BO_ 1427 "Reserved for Zebra BMI. Do not use if possible";
CM_ BO_ 1426 "Reserved for Zebra BMI. Do not use if possible";
CM_ BO_ 1425 "Reserved for Zebra BMI. Do not use if possible";
CM_ BO_ 792 "Reserved for PCU comunication with Zebra BMI. Do not use if possible";
CM_ BO_ 1424 "Reserved for Zebra BMI. Do not use if possible";
CM_ BO_ 1423 "Reserved for Zebra BMI. Do not use if possible";
CM_ BO_ 1422 "Reserved for Zebra BMI. Do not use if possible";
CM_ BO_ 1421 "Reserved for Zebra BMI. Do not use if possible";
CM_ BO_ 1420 "Reserved for Zebra BMI. Do not use if possible";
CM_ BO_ 1419 "Reserved for Zebra BMI. Do not use if possible";
CM_ BO_ 1418 "Reserved for Zebra BMI. Do not use if possible";
CM_ BO_ 1417 "Reserved for Zebra BMI. Do not use if possible";
CM_ BO_ 1416 "Reserved for Zebra BMI. Do not use if possible";
CM_ BO_ 1415 "Reserved for Zebra BMI. Do not use if possible";
CM_ BO_ 791 "Reserved for PCU comunication with Zebra BMI. Do not use if possible";
CM_ BO_ 1414 "Reserved for Zebra BMI. Do not use if possible";
CM_ BO_ 1413 "Reserved for Zebra BMI. Do not use if possible";
CM_ BO_ 1412 "Reserved for Zebra BMI. Do not use if possible";
CM_ BO_ 1411 "Reserved for Zebra BMI. Do not use if possible";
CM_ BO_ 1410 "Reserved for Zebra BMI. Do not use if possible";
CM_ BO_ 1409 "Reserved for Zebra BMI. Do not use if possible";
CM_ BO_ 1408 "Reserved for Zebra BMI. Do not use if possible";
CM_ BO_ 1407 "Reserved for Zebra BMI. Do not use if possible";
CM_ BO_ 1406 "Reserved for Zebra BMI. Do not use if possible";
CM_ BO_ 1405 "Reserved for Zebra BMI. Do not use if possible";
CM_ BO_ 790 "Reserved for PCU comunication with Zebra BMI. Do not use if possible";
CM_ BO_ 1404 "Reserved for Zebra BMI. Do not use if possible";
CM_ BO_ 1403 "Reserved for Zebra BMI. Do not use if possible";
CM_ BO_ 1402 "Reserved for Zebra BMI. Do not use if possible";
CM_ BO_ 1401 "Reserved for Zebra BMI. Do not use if possible";
CM_ BO_ 1400 "Reserved for Zebra BMI. Do not use if possible";
CM_ BO_ 1399 "Reserved for Zebra BMI. Do not use if possible";
CM_ BO_ 1398 "Reserved for Zebra BMI. Do not use if possible";
CM_ BO_ 1397 "Reserved for Zebra BMI. Do not use if possible";
CM_ BO_ 1396 "Reserved for Zebra BMI. Do not use if possible";
CM_ BO_ 1395 "Reserved for Zebra BMI. Do not use if possible";
CM_ BO_ 789 "Reserved for PCU comunication with Zebra BMI. Do not use if possible";
CM_ BO_ 1394 "Reserved for Zebra BMI. Do not use if possible";
CM_ BO_ 1393 "Reserved for Zebra BMI. Do not use if possible";
CM_ BO_ 1392 "Reserved for Zebra BMI. Do not use if possible";
CM_ BO_ 1391 "Reserved for Zebra BMI. Do not use if possible";
CM_ BO_ 1390 "Reserved for Zebra BMI. Do not use if possible";
CM_ BO_ 1389 "Reserved for Zebra BMI. Do not use if possible";
CM_ BO_ 1388 "Reserved for Zebra BMI. Do not use if possible";
CM_ BO_ 1387 "Reserved for Zebra BMI. Do not use if possible";
CM_ BO_ 1386 "Reserved for Zebra BMI. Do not use if possible";
CM_ BO_ 1385 "Reserved for Zebra BMI. Do not use if possible";
CM_ BO_ 788 "Reserved for PCU comunication with Zebra BMI. Do not use if possible";
CM_ BO_ 1384 "Reserved for Zebra BMI. Do not use if possible";
CM_ BO_ 1383 "Reserved for Zebra BMI. Do not use if possible";
CM_ BO_ 1382 "Reserved for Zebra BMI. Do not use if possible";
CM_ BO_ 1381 "Reserved for Zebra BMI. Do not use if possible";
CM_ BO_ 1380 "Reserved for Zebra BMI. Do not use if possible";
CM_ BO_ 1379 "Reserved for Zebra BMI. Do not use if possible";
CM_ BO_ 1378 "Reserved for Zebra BMI. Do not use if possible";
CM_ BO_ 1377 "Reserved for Zebra BMI. Do not use if possible";
CM_ BO_ 1376 "Reserved for Zebra BMI. Do not use if possible";
CM_ BO_ 1375 "Reserved for Zebra BMI. Do not use if possible";
CM_ BO_ 787 "Reserved for PCU comunication with Zebra BMI. Do not use if possible";
CM_ BO_ 144 "A different version of ABS might use this frame. Do not use if possible.";
CM_ BO_ 1374 "Reserved for Zebra BMI. Do not use if possible";
CM_ BO_ 1373 "Reserved for Zebra BMI. Do not use if possible";
CM_ BO_ 1372 "Reserved for Zebra BMI. Do not use if possible";
CM_ BO_ 1371 "Reserved for Zebra BMI. Do not use if possible";
CM_ BO_ 1370 "Reserved for Zebra BMI. Do not use if possible";
CM_ BO_ 1369 "Reserved for Zebra BMI. Do not use if possible";
CM_ BO_ 1368 "Reserved for Zebra BMI. Do not use if possible";
CM_ BO_ 1367 "Reserved for Zebra BMI. Do not use if possible";
CM_ BO_ 1366 "Reserved for Zebra BMI. Do not use if possible";
CM_ BO_ 1365 "Reserved for Zebra BMI. Do not use if possible";
CM_ BO_ 786 "Reserved for PCU comunication with Zebra BMI. Do not use if possible";
CM_ BO_ 1364 "Reserved for Zebra BMI. Do not use if possible";
CM_ BO_ 1363 "Reserved for Zebra BMI. Do not use if possible";
CM_ BO_ 1362 "Reserved for Zebra BMI. Do not use if possible";
CM_ BO_ 1361 "Reserved for Zebra BMI. Do not use if possible";
CM_ BO_ 1360 "Reserved for Zebra BMI. Do not use if possible";
CM_ BO_ 1359 "Reserved for Zebra BMI. Do not use if possible";
CM_ BO_ 1358 "Reserved for Zebra BMI. Do not use if possible";
CM_ BO_ 1357 "Reserved for Zebra BMI. Do not use if possible";
CM_ BO_ 1356 "Reserved for Zebra BMI. Do not use if possible";
CM_ BO_ 1355 "Reserved for Zebra BMI. Do not use if possible";
CM_ BO_ 1354 "Reserved for Zebra BMI. Do not use if possible";
CM_ BO_ 1353 "Reserved for Zebra BMI. Do not use if possible";
CM_ BO_ 1352 "Reserved for Zebra BMI. Do not use if possible";
CM_ BO_ 1351 "Reserved for Zebra BMI. Do not use if possible";
CM_ BO_ 1350 "Reserved for Zebra BMI. Do not use if possible";
CM_ BO_ 1349 "Reserved for Zebra BMI. Do not use if possible";
CM_ BO_ 1348 "Reserved for Zebra BMI. Do not use if possible";
CM_ BO_ 1347 "Reserved for Zebra BMI. Do not use if possible";
CM_ BO_ 1346 "Reserved for Zebra BMI. Do not use if possible";
CM_ BO_ 1345 "Reserved for Zebra BMI. Do not use if possible";
CM_ BO_ 1344 "Reserved for Zebra BMI. Do not use if possible";
CM_ BO_ 1343 "Reserved for Zebra BMI. Do not use if possible";
CM_ BO_ 1342 "Reserved for Zebra BMI. Do not use if possible";
CM_ BO_ 1341 "Reserved for Zebra BMI. Do not use if possible";
CM_ BO_ 1340 "Reserved for Zebra BMI. Do not use if possible";
CM_ BO_ 1339 "Reserved for Zebra BMI. Do not use if possible";
CM_ BO_ 1338 "Reserved for Zebra BMI. Do not use if possible";
CM_ BO_ 1337 "Reserved for Zebra BMI. Do not use if possible";
CM_ BO_ 1336 "Reserved for Zebra BMI. Do not use if possible";
CM_ BO_ 1335 "Reserved for Zebra BMI. Do not use if possible";
CM_ BO_ 781 "Reserved for Zebra BMI. Do not use";
CM_ BO_ 1334 "Reserved for Zebra BMI. Do not use if possible";
CM_ BO_ 1333 "Reserved for Zebra BMI. Do not use if possible";
CM_ BO_ 1332 "Reserved for Zebra BMI. Do not use if possible";
CM_ BO_ 1331 "Reserved for Zebra BMI. Do not use if possible";
CM_ BO_ 1330 "Reserved for Zebra BMI. Do not use if possible";
CM_ BO_ 1329 "Reserved for Zebra BMI. Do not use if possible";
CM_ BO_ 1328 "Reserved for Zebra BMI. Do not use if possible";
CM_ BO_ 1327 "Reserved for Zebra BMI. Do not use if possible";
CM_ BO_ 1326 "Reserved for Zebra BMI. Do not use if possible";
CM_ BO_ 1325 "Reserved for Zebra BMI. Do not use if possible";
CM_ BO_ 780 "Reserved for Zebra BMI. Do not use";
CM_ BO_ 1324 "Reserved for Zebra BMI. Do not use if possible";
BA_DEF_ BO_  "GenMsgCycleTimeFast" INT 0 0;
BA_DEF_ BO_  "GenMsgCycleTime" INT 0 0;
BA_DEF_ BO_  "GenMsgSendType" ENUM  "Cyclic","NotUsed","NotUsed","NotUsed","NotUsed","NotUsed","NotUsed","IfActive","NoMsgSendType","NotUsed";
BA_DEF_ SG_  "GenSigStartValue" FLOAT 0 0;
BA_DEF_ SG_  "GenSigCycleTimeActive" INT 0 0;
BA_DEF_ SG_  "GenSigCycleTime" INT 0 0;
BA_DEF_ SG_  "GenSigSendType" ENUM  "Cyclic","OnWrite","OnWriteWithRepetition","OnChange","OnChangeWithRepetition","IfActive","IfActiveWithRepetition","NoSigSendType","NotUsed","NotUsed","NotUsed","NotUsed","NotUsed";
BA_DEF_  "Baudrate" INT 0 1000000;
BA_DEF_  "BusType" STRING ;
BA_DEF_  "NmType" STRING ;
BA_DEF_  "Manufacturer" STRING ;
BA_DEF_DEF_  "GenMsgCycleTimeFast" 0;
BA_DEF_DEF_  "GenMsgCycleTime" 0;
BA_DEF_DEF_  "GenMsgSendType" "Cyclic";
BA_DEF_DEF_  "GenSigStartValue" 0;
BA_DEF_DEF_  "GenSigCycleTimeActive" 0;
BA_DEF_DEF_  "GenSigCycleTime" 0;
BA_DEF_DEF_  "GenSigSendType" "Cyclic";
BA_DEF_DEF_  "Baudrate" 125000;
BA_DEF_DEF_  "BusType" "";
BA_DEF_DEF_  "NmType" "";
BA_DEF_DEF_  "Manufacturer" "";
BA_ "BusType" "CAN";
BA_ "Baudrate" 500000;
BA_ "GenMsgCycleTime" BO_ 1091 200;
BA_ "GenMsgCycleTimeFast" BO_ 1091 200;
BA_ "GenMsgCycleTime" BO_ 1092 200;
BA_ "GenMsgCycleTimeFast" BO_ 1092 200;
BA_ "GenMsgCycleTime" BO_ 1088 200;
BA_ "GenMsgCycleTimeFast" BO_ 1088 200;
BA_ "GenMsgCycleTime" BO_ 1089 200;
BA_ "GenMsgCycleTimeFast" BO_ 1089 200;
BA_ "GenMsgCycleTime" BO_ 1090 200;
BA_ "GenMsgCycleTimeFast" BO_ 1090 200;
BA_ "GenMsgCycleTime" BO_ 929 500;
BA_ "GenMsgCycleTimeFast" BO_ 929 500;
BA_ "GenMsgCycleTime" BO_ 928 500;
BA_ "GenMsgCycleTimeFast" BO_ 928 500;
BA_ "GenMsgCycleTime" BO_ 592 100;
BA_ "GenMsgCycleTimeFast" BO_ 592 100;
BA_ "GenMsgCycleTime" BO_ 2001 100;
BA_ "GenMsgCycleTimeFast" BO_ 2001 100;
BA_ "GenMsgCycleTime" BO_ 836 200;
BA_ "GenMsgCycleTimeFast" BO_ 836 100;
BA_ "GenMsgCycleTime" BO_ 837 200;
BA_ "GenMsgCycleTimeFast" BO_ 837 100;
BA_ "GenMsgCycleTime" BO_ 1922 100;
BA_ "GenMsgCycleTimeFast" BO_ 1922 100;
BA_ "GenMsgCycleTime" BO_ 838 100;
BA_ "GenMsgCycleTimeFast" BO_ 838 100;
BA_ "GenMsgCycleTime" BO_ 1941 100;
BA_ "GenMsgCycleTimeFast" BO_ 1941 100;
BA_ "GenMsgCycleTime" BO_ 1525 100;
BA_ "GenMsgCycleTimeFast" BO_ 1525 100;
BA_ "GenMsgCycleTime" BO_ 1493 100;
BA_ "GenMsgCycleTimeFast" BO_ 1493 100;
BA_ "GenMsgCycleTime" BO_ 1631 100;
BA_ "GenMsgCycleTimeFast" BO_ 1631 100;
BA_ "GenMsgCycleTime" BO_ 1630 100;
BA_ "GenMsgCycleTimeFast" BO_ 1630 100;
BA_ "GenMsgCycleTime" BO_ 1629 100;
BA_ "GenMsgCycleTimeFast" BO_ 1629 100;
BA_ "GenMsgCycleTime" BO_ 1628 100;
BA_ "GenMsgCycleTimeFast" BO_ 1628 100;
BA_ "GenMsgCycleTime" BO_ 1627 100;
BA_ "GenMsgCycleTimeFast" BO_ 1627 100;
BA_ "GenMsgCycleTime" BO_ 1626 100;
BA_ "GenMsgCycleTimeFast" BO_ 1626 100;
BA_ "GenMsgCycleTime" BO_ 1625 100;
BA_ "GenMsgCycleTimeFast" BO_ 1625 100;
BA_ "GenMsgCycleTime" BO_ 1624 100;
BA_ "GenMsgCycleTimeFast" BO_ 1624 100;
BA_ "GenMsgCycleTime" BO_ 1623 100;
BA_ "GenMsgCycleTimeFast" BO_ 1623 100;
BA_ "GenMsgCycleTime" BO_ 1622 100;
BA_ "GenMsgCycleTimeFast" BO_ 1622 100;
BA_ "GenMsgCycleTime" BO_ 1621 100;
BA_ "GenMsgCycleTimeFast" BO_ 1621 100;
BA_ "GenMsgCycleTime" BO_ 1620 100;
BA_ "GenMsgCycleTimeFast" BO_ 1620 100;
BA_ "GenMsgCycleTime" BO_ 1619 100;
BA_ "GenMsgCycleTimeFast" BO_ 1619 100;
BA_ "GenMsgCycleTime" BO_ 1618 100;
BA_ "GenMsgCycleTimeFast" BO_ 1618 100;
BA_ "GenMsgCycleTime" BO_ 1617 100;
BA_ "GenMsgCycleTimeFast" BO_ 1617 100;
BA_ "GenMsgCycleTime" BO_ 1616 100;
BA_ "GenMsgCycleTimeFast" BO_ 1616 100;
BA_ "GenMsgCycleTime" BO_ 1615 100;
BA_ "GenMsgCycleTimeFast" BO_ 1615 100;
BA_ "GenMsgCycleTime" BO_ 1614 100;
BA_ "GenMsgCycleTimeFast" BO_ 1614 100;
BA_ "GenMsgCycleTime" BO_ 645 100;
BA_ "GenMsgCycleTimeFast" BO_ 645 100;
BA_ "GenMsgCycleTime" BO_ 1613 100;
BA_ "GenMsgCycleTimeFast" BO_ 1613 100;
BA_ "GenMsgCycleTime" BO_ 1612 100;
BA_ "GenMsgCycleTimeFast" BO_ 1612 100;
BA_ "GenMsgCycleTime" BO_ 1611 100;
BA_ "GenMsgCycleTimeFast" BO_ 1611 100;
BA_ "GenMsgCycleTime" BO_ 1610 100;
BA_ "GenMsgCycleTimeFast" BO_ 1610 100;
BA_ "GenMsgCycleTime" BO_ 1609 100;
BA_ "GenMsgCycleTimeFast" BO_ 1609 100;
BA_ "GenMsgCycleTime" BO_ 1608 100;
BA_ "GenMsgCycleTimeFast" BO_ 1608 100;
BA_ "GenMsgCycleTime" BO_ 1607 100;
BA_ "GenMsgCycleTimeFast" BO_ 1607 100;
BA_ "GenMsgCycleTime" BO_ 1606 200;
BA_ "GenMsgCycleTimeFast" BO_ 1606 100;
BA_ "GenMsgCycleTime" BO_ 1605 100;
BA_ "GenMsgCycleTimeFast" BO_ 1605 100;
BA_ "GenMsgCycleTime" BO_ 1604 200;
BA_ "GenMsgCycleTimeFast" BO_ 1604 100;
BA_ "GenMsgCycleTime" BO_ 513 100;
BA_ "GenMsgCycleTimeFast" BO_ 513 100;
BA_ "GenMsgCycleTime" BO_ 1603 100;
BA_ "GenMsgCycleTimeFast" BO_ 1603 100;
BA_ "GenMsgCycleTime" BO_ 1602 200;
BA_ "GenMsgCycleTimeFast" BO_ 1602 100;
BA_ "GenMsgCycleTime" BO_ 1601 100;
BA_ "GenMsgCycleTimeFast" BO_ 1601 100;
BA_ "GenMsgCycleTime" BO_ 1600 100;
BA_ "GenMsgCycleTimeFast" BO_ 1600 100;
BA_ "GenMsgCycleTime" BO_ 1584 100;
BA_ "GenMsgCycleTimeFast" BO_ 1584 100;
BA_ "GenMsgCycleTime" BO_ 831 100;
BA_ "GenMsgCycleTimeFast" BO_ 831 100;
BA_ "GenMsgCycleTime" BO_ 830 100;
BA_ "GenMsgCycleTimeFast" BO_ 830 100;
BA_ "GenMsgCycleTime" BO_ 829 100;
BA_ "GenMsgCycleTimeFast" BO_ 829 100;
BA_ "GenMsgCycleTime" BO_ 828 100;
BA_ "GenMsgCycleTimeFast" BO_ 828 100;
BA_ "GenMsgCycleTime" BO_ 827 100;
BA_ "GenMsgCycleTimeFast" BO_ 827 100;
BA_ "GenMsgCycleTime" BO_ 512 100;
BA_ "GenMsgCycleTimeFast" BO_ 512 100;
BA_ "GenMsgCycleTime" BO_ 826 100;
BA_ "GenMsgCycleTimeFast" BO_ 826 100;
BA_ "GenMsgCycleTime" BO_ 825 100;
BA_ "GenMsgCycleTimeFast" BO_ 825 100;
BA_ "GenMsgCycleTime" BO_ 824 100;
BA_ "GenMsgCycleTimeFast" BO_ 824 100;
BA_ "GenMsgCycleTime" BO_ 823 100;
BA_ "GenMsgCycleTimeFast" BO_ 823 100;
BA_ "GenMsgCycleTime" BO_ 822 100;
BA_ "GenMsgCycleTimeFast" BO_ 822 100;
BA_ "GenMsgCycleTime" BO_ 821 100;
BA_ "GenMsgCycleTimeFast" BO_ 821 100;
BA_ "GenMsgCycleTime" BO_ 820 100;
BA_ "GenMsgCycleTimeFast" BO_ 820 100;
BA_ "GenMsgCycleTime" BO_ 819 100;
BA_ "GenMsgCycleTimeFast" BO_ 819 100;
BA_ "GenMsgCycleTime" BO_ 818 100;
BA_ "GenMsgCycleTimeFast" BO_ 818 100;
BA_ "GenMsgCycleTime" BO_ 817 100;
BA_ "GenMsgCycleTimeFast" BO_ 817 100;
BA_ "GenMsgCycleTime" BO_ 1568 100;
BA_ "GenMsgCycleTimeFast" BO_ 1568 100;
BA_ "GenMsgCycleTime" BO_ 816 100;
BA_ "GenMsgCycleTimeFast" BO_ 816 100;
BA_ "GenMsgCycleTime" BO_ 815 100;
BA_ "GenMsgCycleTimeFast" BO_ 815 100;
BA_ "GenMsgCycleTime" BO_ 814 100;
BA_ "GenMsgCycleTimeFast" BO_ 814 100;
BA_ "GenMsgCycleTime" BO_ 813 100;
BA_ "GenMsgCycleTimeFast" BO_ 813 100;
BA_ "GenMsgCycleTime" BO_ 812 100;
BA_ "GenMsgCycleTimeFast" BO_ 812 100;
BA_ "GenMsgCycleTime" BO_ 811 100;
BA_ "GenMsgCycleTimeFast" BO_ 811 100;
BA_ "GenMsgCycleTime" BO_ 810 100;
BA_ "GenMsgCycleTimeFast" BO_ 810 100;
BA_ "GenMsgCycleTime" BO_ 809 100;
BA_ "GenMsgCycleTimeFast" BO_ 809 100;
BA_ "GenMsgCycleTime" BO_ 808 100;
BA_ "GenMsgCycleTimeFast" BO_ 808 100;
BA_ "GenMsgCycleTime" BO_ 1892 100;
BA_ "GenMsgCycleTimeFast" BO_ 1892 100;
BA_ "GenMsgCycleTime" BO_ 1888 100;
BA_ "GenMsgCycleTimeFast" BO_ 1888 100;
BA_ "GenMsgCycleTime" BO_ 807 100;
BA_ "GenMsgCycleTimeFast" BO_ 807 100;
BA_ "GenMsgCycleTime" BO_ 1072 100;
BA_ "GenMsgCycleTimeFast" BO_ 1072 100;
BA_ "GenMsgCycleTime" BO_ 1034 100;
BA_ "GenMsgCycleTimeFast" BO_ 1034 100;
BA_ "GenMsgCycleTime" BO_ 1585 100;
BA_ "GenMsgCycleTimeFast" BO_ 1585 100;
BA_ "GenMsgCycleTime" BO_ 1569 100;
BA_ "GenMsgCycleTimeFast" BO_ 1569 100;
BA_ "GenMsgCycleTime" BO_ 857 100;
BA_ "GenMsgCycleTimeFast" BO_ 857 100;
BA_ "GenMsgCycleTime" BO_ 1567 100;
BA_ "GenMsgCycleTimeFast" BO_ 1567 100;
BA_ "GenMsgCycleTime" BO_ 1566 100;
BA_ "GenMsgCycleTimeFast" BO_ 1566 100;
BA_ "GenMsgCycleTime" BO_ 806 100;
BA_ "GenMsgCycleTimeFast" BO_ 806 100;
BA_ "GenMsgCycleTime" BO_ 1565 100;
BA_ "GenMsgCycleTimeFast" BO_ 1565 100;
BA_ "GenMsgCycleTime" BO_ 1564 100;
BA_ "GenMsgCycleTimeFast" BO_ 1564 100;
BA_ "GenMsgCycleTime" BO_ 1563 100;
BA_ "GenMsgCycleTimeFast" BO_ 1563 100;
BA_ "GenMsgCycleTime" BO_ 1562 100;
BA_ "GenMsgCycleTimeFast" BO_ 1562 100;
BA_ "GenMsgCycleTime" BO_ 1561 100;
BA_ "GenMsgCycleTimeFast" BO_ 1561 100;
BA_ "GenMsgCycleTime" BO_ 1560 100;
BA_ "GenMsgCycleTimeFast" BO_ 1560 100;
BA_ "GenMsgCycleTime" BO_ 1559 100;
BA_ "GenMsgCycleTimeFast" BO_ 1559 100;
BA_ "GenMsgCycleTime" BO_ 1558 100;
BA_ "GenMsgCycleTimeFast" BO_ 1558 100;
BA_ "GenMsgCycleTime" BO_ 1557 100;
BA_ "GenMsgCycleTimeFast" BO_ 1557 100;
BA_ "GenMsgCycleTime" BO_ 1556 100;
BA_ "GenMsgCycleTimeFast" BO_ 1556 100;
BA_ "GenMsgCycleTime" BO_ 805 100;
BA_ "GenMsgCycleTimeFast" BO_ 805 100;
BA_ "GenMsgCycleTime" BO_ 1555 100;
BA_ "GenMsgCycleTimeFast" BO_ 1555 100;
BA_ "GenMsgCycleTime" BO_ 1554 100;
BA_ "GenMsgCycleTimeFast" BO_ 1554 100;
BA_ "GenMsgCycleTime" BO_ 1553 100;
BA_ "GenMsgCycleTimeFast" BO_ 1553 100;
BA_ "GenMsgCycleTime" BO_ 1552 100;
BA_ "GenMsgCycleTimeFast" BO_ 1552 100;
BA_ "GenMsgCycleTime" BO_ 1551 100;
BA_ "GenMsgCycleTimeFast" BO_ 1551 100;
BA_ "GenMsgCycleTime" BO_ 1550 100;
BA_ "GenMsgCycleTimeFast" BO_ 1550 100;
BA_ "GenMsgCycleTime" BO_ 1549 100;
BA_ "GenMsgCycleTimeFast" BO_ 1549 100;
BA_ "GenMsgCycleTime" BO_ 1548 100;
BA_ "GenMsgCycleTimeFast" BO_ 1548 100;
BA_ "GenMsgCycleTime" BO_ 1547 100;
BA_ "GenMsgCycleTimeFast" BO_ 1547 100;
BA_ "GenMsgCycleTime" BO_ 804 100;
BA_ "GenMsgCycleTimeFast" BO_ 804 100;
BA_ "GenMsgCycleTime" BO_ 1546 100;
BA_ "GenMsgCycleTimeFast" BO_ 1546 100;
BA_ "GenMsgCycleTime" BO_ 1545 100;
BA_ "GenMsgCycleTimeFast" BO_ 1545 100;
BA_ "GenMsgCycleTime" BO_ 1544 100;
BA_ "GenMsgCycleTimeFast" BO_ 1544 100;
BA_ "GenMsgCycleTime" BO_ 1543 100;
BA_ "GenMsgCycleTimeFast" BO_ 1543 100;
BA_ "GenMsgCycleTime" BO_ 1542 100;
BA_ "GenMsgCycleTimeFast" BO_ 1542 100;
BA_ "GenMsgCycleTime" BO_ 1541 100;
BA_ "GenMsgCycleTimeFast" BO_ 1541 100;
BA_ "GenMsgCycleTime" BO_ 1540 100;
BA_ "GenMsgCycleTimeFast" BO_ 1540 100;
BA_ "GenMsgCycleTime" BO_ 1539 100;
BA_ "GenMsgCycleTimeFast" BO_ 1539 100;
BA_ "GenMsgCycleTime" BO_ 1538 100;
BA_ "GenMsgCycleTimeFast" BO_ 1538 100;
BA_ "GenMsgCycleTime" BO_ 1537 100;
BA_ "GenMsgCycleTimeFast" BO_ 1537 100;
BA_ "GenMsgCycleTime" BO_ 803 100;
BA_ "GenMsgCycleTimeFast" BO_ 803 100;
BA_ "GenMsgCycleTime" BO_ 1536 100;
BA_ "GenMsgCycleTimeFast" BO_ 1536 100;
BA_ "GenMsgCycleTime" BO_ 1535 100;
BA_ "GenMsgCycleTimeFast" BO_ 1535 100;
BA_ "GenMsgCycleTime" BO_ 1534 100;
BA_ "GenMsgCycleTimeFast" BO_ 1534 100;
BA_ "GenMsgCycleTime" BO_ 1533 100;
BA_ "GenMsgCycleTimeFast" BO_ 1533 100;
BA_ "GenMsgCycleTime" BO_ 1532 100;
BA_ "GenMsgCycleTimeFast" BO_ 1532 100;
BA_ "GenMsgCycleTime" BO_ 1531 100;
BA_ "GenMsgCycleTimeFast" BO_ 1531 100;
BA_ "GenMsgCycleTime" BO_ 1530 100;
BA_ "GenMsgCycleTimeFast" BO_ 1530 100;
BA_ "GenMsgCycleTime" BO_ 1529 100;
BA_ "GenMsgCycleTimeFast" BO_ 1529 100;
BA_ "GenMsgCycleTime" BO_ 1528 100;
BA_ "GenMsgCycleTimeFast" BO_ 1528 100;
BA_ "GenMsgCycleTime" BO_ 1527 100;
BA_ "GenMsgCycleTimeFast" BO_ 1527 100;
BA_ "GenMsgCycleTime" BO_ 802 100;
BA_ "GenMsgCycleTimeFast" BO_ 802 100;
BA_ "GenMsgCycleTime" BO_ 1526 100;
BA_ "GenMsgCycleTimeFast" BO_ 1526 100;
BA_ "GenMsgCycleTime" BO_ 1524 100;
BA_ "GenMsgCycleTimeFast" BO_ 1524 100;
BA_ "GenMsgCycleTime" BO_ 1523 100;
BA_ "GenMsgCycleTimeFast" BO_ 1523 100;
BA_ "GenMsgCycleTime" BO_ 1522 100;
BA_ "GenMsgCycleTimeFast" BO_ 1522 100;
BA_ "GenMsgCycleTime" BO_ 1521 100;
BA_ "GenMsgCycleTimeFast" BO_ 1521 100;
BA_ "GenMsgCycleTime" BO_ 1520 100;
BA_ "GenMsgCycleTimeFast" BO_ 1520 100;
BA_ "GenMsgCycleTime" BO_ 1519 100;
BA_ "GenMsgCycleTimeFast" BO_ 1519 100;
BA_ "GenMsgCycleTime" BO_ 1518 100;
BA_ "GenMsgCycleTimeFast" BO_ 1518 100;
BA_ "GenMsgCycleTime" BO_ 1517 100;
BA_ "GenMsgCycleTimeFast" BO_ 1517 100;
BA_ "GenMsgCycleTime" BO_ 1516 100;
BA_ "GenMsgCycleTimeFast" BO_ 1516 100;
BA_ "GenMsgCycleTime" BO_ 801 100;
BA_ "GenMsgCycleTimeFast" BO_ 801 100;
BA_ "GenMsgCycleTime" BO_ 1515 100;
BA_ "GenMsgCycleTimeFast" BO_ 1515 100;
BA_ "GenMsgCycleTime" BO_ 1514 100;
BA_ "GenMsgCycleTimeFast" BO_ 1514 100;
BA_ "GenMsgCycleTime" BO_ 1513 100;
BA_ "GenMsgCycleTimeFast" BO_ 1513 100;
BA_ "GenMsgCycleTime" BO_ 1512 100;
BA_ "GenMsgCycleTimeFast" BO_ 1512 100;
BA_ "GenMsgCycleTime" BO_ 1511 100;
BA_ "GenMsgCycleTimeFast" BO_ 1511 100;
BA_ "GenMsgCycleTime" BO_ 1510 100;
BA_ "GenMsgCycleTimeFast" BO_ 1510 100;
BA_ "GenMsgCycleTime" BO_ 1509 100;
BA_ "GenMsgCycleTimeFast" BO_ 1509 100;
BA_ "GenMsgCycleTime" BO_ 1508 100;
BA_ "GenMsgCycleTimeFast" BO_ 1508 100;
BA_ "GenMsgCycleTime" BO_ 1507 100;
BA_ "GenMsgCycleTimeFast" BO_ 1507 100;
BA_ "GenMsgCycleTime" BO_ 1506 100;
BA_ "GenMsgCycleTimeFast" BO_ 1506 100;
BA_ "GenMsgCycleTime" BO_ 800 100;
BA_ "GenMsgCycleTimeFast" BO_ 800 100;
BA_ "GenMsgCycleTime" BO_ 1505 100;
BA_ "GenMsgCycleTimeFast" BO_ 1505 100;
BA_ "GenMsgCycleTime" BO_ 1504 100;
BA_ "GenMsgCycleTimeFast" BO_ 1504 100;
BA_ "GenMsgCycleTime" BO_ 1503 100;
BA_ "GenMsgCycleTimeFast" BO_ 1503 100;
BA_ "GenMsgCycleTime" BO_ 1502 100;
BA_ "GenMsgCycleTimeFast" BO_ 1502 100;
BA_ "GenMsgCycleTime" BO_ 1501 100;
BA_ "GenMsgCycleTimeFast" BO_ 1501 100;
BA_ "GenMsgCycleTime" BO_ 1500 100;
BA_ "GenMsgCycleTimeFast" BO_ 1500 100;
BA_ "GenMsgCycleTime" BO_ 1499 100;
BA_ "GenMsgCycleTimeFast" BO_ 1499 100;
BA_ "GenMsgCycleTime" BO_ 1498 100;
BA_ "GenMsgCycleTimeFast" BO_ 1498 100;
BA_ "GenMsgCycleTime" BO_ 1497 100;
BA_ "GenMsgCycleTimeFast" BO_ 1497 100;
BA_ "GenMsgCycleTime" BO_ 1496 100;
BA_ "GenMsgCycleTimeFast" BO_ 1496 100;
BA_ "GenMsgCycleTime" BO_ 799 100;
BA_ "GenMsgCycleTimeFast" BO_ 799 100;
BA_ "GenMsgCycleTime" BO_ 1495 100;
BA_ "GenMsgCycleTimeFast" BO_ 1495 100;
BA_ "GenMsgCycleTime" BO_ 1494 100;
BA_ "GenMsgCycleTimeFast" BO_ 1494 100;
BA_ "GenMsgCycleTime" BO_ 1492 100;
BA_ "GenMsgCycleTimeFast" BO_ 1492 100;
BA_ "GenMsgCycleTime" BO_ 1491 100;
BA_ "GenMsgCycleTimeFast" BO_ 1491 100;
BA_ "GenMsgCycleTime" BO_ 1490 100;
BA_ "GenMsgCycleTimeFast" BO_ 1490 100;
BA_ "GenMsgCycleTime" BO_ 1489 100;
BA_ "GenMsgCycleTimeFast" BO_ 1489 100;
BA_ "GenMsgCycleTime" BO_ 1488 100;
BA_ "GenMsgCycleTimeFast" BO_ 1488 100;
BA_ "GenMsgCycleTime" BO_ 1487 100;
BA_ "GenMsgCycleTimeFast" BO_ 1487 100;
BA_ "GenMsgCycleTime" BO_ 1486 100;
BA_ "GenMsgCycleTimeFast" BO_ 1486 100;
BA_ "GenMsgCycleTime" BO_ 1485 100;
BA_ "GenMsgCycleTimeFast" BO_ 1485 100;
BA_ "GenMsgCycleTime" BO_ 798 100;
BA_ "GenMsgCycleTimeFast" BO_ 798 100;
BA_ "GenMsgCycleTime" BO_ 1484 100;
BA_ "GenMsgCycleTimeFast" BO_ 1484 100;
BA_ "GenMsgCycleTime" BO_ 1483 100;
BA_ "GenMsgCycleTimeFast" BO_ 1483 100;
BA_ "GenMsgCycleTime" BO_ 1482 100;
BA_ "GenMsgCycleTimeFast" BO_ 1482 100;
BA_ "GenMsgCycleTime" BO_ 1481 100;
BA_ "GenMsgCycleTimeFast" BO_ 1481 100;
BA_ "GenMsgCycleTime" BO_ 1480 100;
BA_ "GenMsgCycleTimeFast" BO_ 1480 100;
BA_ "GenMsgCycleTime" BO_ 1479 100;
BA_ "GenMsgCycleTimeFast" BO_ 1479 100;
BA_ "GenMsgCycleTime" BO_ 1478 100;
BA_ "GenMsgCycleTimeFast" BO_ 1478 100;
BA_ "GenMsgCycleTime" BO_ 1477 100;
BA_ "GenMsgCycleTimeFast" BO_ 1477 100;
BA_ "GenMsgCycleTime" BO_ 1476 100;
BA_ "GenMsgCycleTimeFast" BO_ 1476 100;
BA_ "GenMsgCycleTime" BO_ 1475 100;
BA_ "GenMsgCycleTimeFast" BO_ 1475 100;
BA_ "GenMsgCycleTime" BO_ 797 100;
BA_ "GenMsgCycleTimeFast" BO_ 797 100;
BA_ "GenMsgCycleTime" BO_ 560 100;
BA_ "GenMsgCycleTimeFast" BO_ 560 100;
BA_ "GenMsgCycleTime" BO_ 1474 100;
BA_ "GenMsgCycleTimeFast" BO_ 1474 100;
BA_ "GenMsgCycleTime" BO_ 1473 100;
BA_ "GenMsgCycleTimeFast" BO_ 1473 100;
BA_ "GenMsgCycleTime" BO_ 1472 100;
BA_ "GenMsgCycleTimeFast" BO_ 1472 100;
BA_ "GenMsgCycleTime" BO_ 1471 100;
BA_ "GenMsgCycleTimeFast" BO_ 1471 100;
BA_ "GenMsgCycleTime" BO_ 1470 100;
BA_ "GenMsgCycleTimeFast" BO_ 1470 100;
BA_ "GenMsgCycleTime" BO_ 1469 100;
BA_ "GenMsgCycleTimeFast" BO_ 1469 100;
BA_ "GenMsgCycleTime" BO_ 1468 100;
BA_ "GenMsgCycleTimeFast" BO_ 1468 100;
BA_ "GenMsgCycleTime" BO_ 1467 100;
BA_ "GenMsgCycleTimeFast" BO_ 1467 100;
BA_ "GenMsgCycleTime" BO_ 1466 100;
BA_ "GenMsgCycleTimeFast" BO_ 1466 100;
BA_ "GenMsgCycleTime" BO_ 1465 100;
BA_ "GenMsgCycleTimeFast" BO_ 1465 100;
BA_ "GenMsgCycleTime" BO_ 796 100;
BA_ "GenMsgCycleTimeFast" BO_ 796 100;
BA_ "GenMsgCycleTime" BO_ 1464 100;
BA_ "GenMsgCycleTimeFast" BO_ 1464 100;
BA_ "GenMsgCycleTime" BO_ 1463 100;
BA_ "GenMsgCycleTimeFast" BO_ 1463 100;
BA_ "GenMsgCycleTime" BO_ 1462 100;
BA_ "GenMsgCycleTimeFast" BO_ 1462 100;
BA_ "GenMsgCycleTime" BO_ 1461 100;
BA_ "GenMsgCycleTimeFast" BO_ 1461 100;
BA_ "GenMsgCycleTime" BO_ 1460 100;
BA_ "GenMsgCycleTimeFast" BO_ 1460 100;
BA_ "GenMsgCycleTime" BO_ 1459 100;
BA_ "GenMsgCycleTimeFast" BO_ 1459 100;
BA_ "GenMsgCycleTime" BO_ 1458 100;
BA_ "GenMsgCycleTimeFast" BO_ 1458 100;
BA_ "GenMsgCycleTime" BO_ 1457 100;
BA_ "GenMsgCycleTimeFast" BO_ 1457 100;
BA_ "GenMsgCycleTime" BO_ 1456 100;
BA_ "GenMsgCycleTimeFast" BO_ 1456 100;
BA_ "GenMsgCycleTime" BO_ 1455 100;
BA_ "GenMsgCycleTimeFast" BO_ 1455 100;
BA_ "GenMsgCycleTime" BO_ 795 100;
BA_ "GenMsgCycleTimeFast" BO_ 795 100;
BA_ "GenMsgCycleTime" BO_ 1454 100;
BA_ "GenMsgCycleTimeFast" BO_ 1454 100;
BA_ "GenMsgCycleTime" BO_ 1453 100;
BA_ "GenMsgCycleTimeFast" BO_ 1453 100;
BA_ "GenMsgCycleTime" BO_ 1452 100;
BA_ "GenMsgCycleTimeFast" BO_ 1452 100;
BA_ "GenMsgCycleTime" BO_ 1451 100;
BA_ "GenMsgCycleTimeFast" BO_ 1451 100;
BA_ "GenMsgCycleTime" BO_ 1450 100;
BA_ "GenMsgCycleTimeFast" BO_ 1450 100;
BA_ "GenMsgCycleTime" BO_ 1449 100;
BA_ "GenMsgCycleTimeFast" BO_ 1449 100;
BA_ "GenMsgCycleTime" BO_ 1448 100;
BA_ "GenMsgCycleTimeFast" BO_ 1448 100;
BA_ "GenMsgCycleTime" BO_ 1447 100;
BA_ "GenMsgCycleTimeFast" BO_ 1447 100;
BA_ "GenMsgCycleTime" BO_ 1446 100;
BA_ "GenMsgCycleTimeFast" BO_ 1446 100;
BA_ "GenMsgCycleTime" BO_ 1445 100;
BA_ "GenMsgCycleTimeFast" BO_ 1445 100;
BA_ "GenMsgCycleTime" BO_ 794 100;
BA_ "GenMsgCycleTimeFast" BO_ 794 100;
BA_ "GenMsgCycleTime" BO_ 1444 100;
BA_ "GenMsgCycleTimeFast" BO_ 1444 100;
BA_ "GenMsgCycleTime" BO_ 1443 100;
BA_ "GenMsgCycleTimeFast" BO_ 1443 100;
BA_ "GenMsgCycleTime" BO_ 1442 100;
BA_ "GenMsgCycleTimeFast" BO_ 1442 100;
BA_ "GenMsgCycleTime" BO_ 1441 100;
BA_ "GenMsgCycleTimeFast" BO_ 1441 100;
BA_ "GenMsgCycleTime" BO_ 1440 100;
BA_ "GenMsgCycleTimeFast" BO_ 1440 100;
BA_ "GenMsgCycleTime" BO_ 1439 100;
BA_ "GenMsgCycleTimeFast" BO_ 1439 100;
BA_ "GenMsgCycleTime" BO_ 1438 100;
BA_ "GenMsgCycleTimeFast" BO_ 1438 100;
BA_ "GenMsgCycleTime" BO_ 1437 100;
BA_ "GenMsgCycleTimeFast" BO_ 1437 100;
BA_ "GenMsgCycleTime" BO_ 1436 100;
BA_ "GenMsgCycleTimeFast" BO_ 1436 100;
BA_ "GenMsgCycleTime" BO_ 1435 100;
BA_ "GenMsgCycleTimeFast" BO_ 1435 100;
BA_ "GenMsgCycleTime" BO_ 793 100;
BA_ "GenMsgCycleTimeFast" BO_ 793 100;
BA_ "GenMsgCycleTime" BO_ 1434 100;
BA_ "GenMsgCycleTimeFast" BO_ 1434 100;
BA_ "GenMsgCycleTime" BO_ 1433 100;
BA_ "GenMsgCycleTimeFast" BO_ 1433 100;
BA_ "GenMsgCycleTime" BO_ 1432 100;
BA_ "GenMsgCycleTimeFast" BO_ 1432 100;
BA_ "GenMsgCycleTime" BO_ 1431 100;
BA_ "GenMsgCycleTimeFast" BO_ 1431 100;
BA_ "GenMsgCycleTime" BO_ 1430 100;
BA_ "GenMsgCycleTimeFast" BO_ 1430 100;
BA_ "GenMsgCycleTime" BO_ 1429 100;
BA_ "GenMsgCycleTimeFast" BO_ 1429 100;
BA_ "GenMsgCycleTime" BO_ 1428 100;
BA_ "GenMsgCycleTimeFast" BO_ 1428 100;
BA_ "GenMsgCycleTime" BO_ 1427 100;
BA_ "GenMsgCycleTimeFast" BO_ 1427 100;
BA_ "GenMsgCycleTime" BO_ 1426 100;
BA_ "GenMsgCycleTimeFast" BO_ 1426 100;
BA_ "GenMsgCycleTime" BO_ 1425 100;
BA_ "GenMsgCycleTimeFast" BO_ 1425 100;
BA_ "GenMsgCycleTime" BO_ 792 100;
BA_ "GenMsgCycleTimeFast" BO_ 792 100;
BA_ "GenMsgCycleTime" BO_ 1424 100;
BA_ "GenMsgCycleTimeFast" BO_ 1424 100;
BA_ "GenMsgCycleTime" BO_ 1423 100;
BA_ "GenMsgCycleTimeFast" BO_ 1423 100;
BA_ "GenMsgCycleTime" BO_ 1422 100;
BA_ "GenMsgCycleTimeFast" BO_ 1422 100;
BA_ "GenMsgCycleTime" BO_ 1421 100;
BA_ "GenMsgCycleTimeFast" BO_ 1421 100;
BA_ "GenMsgCycleTime" BO_ 1420 100;
BA_ "GenMsgCycleTimeFast" BO_ 1420 100;
BA_ "GenMsgCycleTime" BO_ 1419 100;
BA_ "GenMsgCycleTimeFast" BO_ 1419 100;
BA_ "GenMsgCycleTime" BO_ 1418 100;
BA_ "GenMsgCycleTimeFast" BO_ 1418 100;
BA_ "GenMsgCycleTime" BO_ 1417 100;
BA_ "GenMsgCycleTimeFast" BO_ 1417 100;
BA_ "GenMsgCycleTime" BO_ 1416 100;
BA_ "GenMsgCycleTimeFast" BO_ 1416 100;
BA_ "GenMsgCycleTime" BO_ 1415 100;
BA_ "GenMsgCycleTimeFast" BO_ 1415 100;
BA_ "GenMsgCycleTime" BO_ 791 100;
BA_ "GenMsgCycleTimeFast" BO_ 791 100;
BA_ "GenMsgCycleTime" BO_ 1414 100;
BA_ "GenMsgCycleTimeFast" BO_ 1414 100;
BA_ "GenMsgCycleTime" BO_ 1413 100;
BA_ "GenMsgCycleTimeFast" BO_ 1413 100;
BA_ "GenMsgCycleTime" BO_ 1412 100;
BA_ "GenMsgCycleTimeFast" BO_ 1412 100;
BA_ "GenMsgCycleTime" BO_ 1411 100;
BA_ "GenMsgCycleTimeFast" BO_ 1411 100;
BA_ "GenMsgCycleTime" BO_ 1410 100;
BA_ "GenMsgCycleTimeFast" BO_ 1410 100;
BA_ "GenMsgCycleTime" BO_ 1409 100;
BA_ "GenMsgCycleTimeFast" BO_ 1409 100;
BA_ "GenMsgCycleTime" BO_ 1408 100;
BA_ "GenMsgCycleTimeFast" BO_ 1408 100;
BA_ "GenMsgCycleTime" BO_ 1407 100;
BA_ "GenMsgCycleTimeFast" BO_ 1407 100;
BA_ "GenMsgCycleTime" BO_ 1406 100;
BA_ "GenMsgCycleTimeFast" BO_ 1406 100;
BA_ "GenMsgCycleTime" BO_ 1405 100;
BA_ "GenMsgCycleTimeFast" BO_ 1405 100;
BA_ "GenMsgCycleTime" BO_ 790 100;
BA_ "GenMsgCycleTimeFast" BO_ 790 100;
BA_ "GenMsgCycleTime" BO_ 1404 100;
BA_ "GenMsgCycleTimeFast" BO_ 1404 100;
BA_ "GenMsgCycleTime" BO_ 1403 100;
BA_ "GenMsgCycleTimeFast" BO_ 1403 100;
BA_ "GenMsgCycleTime" BO_ 1402 100;
BA_ "GenMsgCycleTimeFast" BO_ 1402 100;
BA_ "GenMsgCycleTime" BO_ 1401 100;
BA_ "GenMsgCycleTimeFast" BO_ 1401 100;
BA_ "GenMsgCycleTime" BO_ 1400 100;
BA_ "GenMsgCycleTimeFast" BO_ 1400 100;
BA_ "GenMsgCycleTime" BO_ 1399 100;
BA_ "GenMsgCycleTimeFast" BO_ 1399 100;
BA_ "GenMsgCycleTime" BO_ 1398 100;
BA_ "GenMsgCycleTimeFast" BO_ 1398 100;
BA_ "GenMsgCycleTime" BO_ 1397 100;
BA_ "GenMsgCycleTimeFast" BO_ 1397 100;
BA_ "GenMsgCycleTime" BO_ 1396 100;
BA_ "GenMsgCycleTimeFast" BO_ 1396 100;
BA_ "GenMsgCycleTime" BO_ 1395 100;
BA_ "GenMsgCycleTimeFast" BO_ 1395 100;
BA_ "GenMsgCycleTime" BO_ 789 100;
BA_ "GenMsgCycleTimeFast" BO_ 789 100;
BA_ "GenMsgCycleTime" BO_ 1394 100;
BA_ "GenMsgCycleTimeFast" BO_ 1394 100;
BA_ "GenMsgCycleTime" BO_ 1393 100;
BA_ "GenMsgCycleTimeFast" BO_ 1393 100;
BA_ "GenMsgCycleTime" BO_ 1392 100;
BA_ "GenMsgCycleTimeFast" BO_ 1392 100;
BA_ "GenMsgCycleTime" BO_ 1391 100;
BA_ "GenMsgCycleTimeFast" BO_ 1391 100;
BA_ "GenMsgCycleTime" BO_ 1390 100;
BA_ "GenMsgCycleTimeFast" BO_ 1390 100;
BA_ "GenMsgCycleTime" BO_ 1389 100;
BA_ "GenMsgCycleTimeFast" BO_ 1389 100;
BA_ "GenMsgCycleTime" BO_ 1388 100;
BA_ "GenMsgCycleTimeFast" BO_ 1388 100;
BA_ "GenMsgCycleTime" BO_ 1387 100;
BA_ "GenMsgCycleTimeFast" BO_ 1387 100;
BA_ "GenMsgCycleTime" BO_ 1386 100;
BA_ "GenMsgCycleTimeFast" BO_ 1386 100;
BA_ "GenMsgCycleTime" BO_ 1385 100;
BA_ "GenMsgCycleTimeFast" BO_ 1385 100;
BA_ "GenMsgCycleTime" BO_ 788 100;
BA_ "GenMsgCycleTimeFast" BO_ 788 100;
BA_ "GenMsgCycleTime" BO_ 1384 100;
BA_ "GenMsgCycleTimeFast" BO_ 1384 100;
BA_ "GenMsgCycleTime" BO_ 1383 100;
BA_ "GenMsgCycleTimeFast" BO_ 1383 100;
BA_ "GenMsgCycleTime" BO_ 1382 100;
BA_ "GenMsgCycleTimeFast" BO_ 1382 100;
BA_ "GenMsgCycleTime" BO_ 1381 100;
BA_ "GenMsgCycleTimeFast" BO_ 1381 100;
BA_ "GenMsgCycleTime" BO_ 1380 100;
BA_ "GenMsgCycleTimeFast" BO_ 1380 100;
BA_ "GenMsgCycleTime" BO_ 1379 100;
BA_ "GenMsgCycleTimeFast" BO_ 1379 100;
BA_ "GenMsgCycleTime" BO_ 1378 100;
BA_ "GenMsgCycleTimeFast" BO_ 1378 100;
BA_ "GenMsgCycleTime" BO_ 1377 100;
BA_ "GenMsgCycleTimeFast" BO_ 1377 100;
BA_ "GenMsgCycleTime" BO_ 1376 100;
BA_ "GenMsgCycleTimeFast" BO_ 1376 100;
BA_ "GenMsgCycleTime" BO_ 1375 100;
BA_ "GenMsgCycleTimeFast" BO_ 1375 100;
BA_ "GenMsgCycleTime" BO_ 787 100;
BA_ "GenMsgCycleTimeFast" BO_ 787 100;
BA_ "GenMsgCycleTime" BO_ 144 100;
BA_ "GenMsgCycleTimeFast" BO_ 144 100;
BA_ "GenMsgCycleTime" BO_ 1374 100;
BA_ "GenMsgCycleTimeFast" BO_ 1374 100;
BA_ "GenMsgCycleTime" BO_ 1373 100;
BA_ "GenMsgCycleTimeFast" BO_ 1373 100;
BA_ "GenMsgCycleTime" BO_ 1372 100;
BA_ "GenMsgCycleTimeFast" BO_ 1372 100;
BA_ "GenMsgCycleTime" BO_ 1371 100;
BA_ "GenMsgCycleTimeFast" BO_ 1371 100;
BA_ "GenMsgCycleTime" BO_ 1370 100;
BA_ "GenMsgCycleTimeFast" BO_ 1370 100;
BA_ "GenMsgCycleTime" BO_ 1369 100;
BA_ "GenMsgCycleTimeFast" BO_ 1369 100;
BA_ "GenMsgCycleTime" BO_ 1368 100;
BA_ "GenMsgCycleTimeFast" BO_ 1368 100;
BA_ "GenMsgCycleTime" BO_ 1367 100;
BA_ "GenMsgCycleTimeFast" BO_ 1367 100;
BA_ "GenMsgCycleTime" BO_ 1366 100;
BA_ "GenMsgCycleTimeFast" BO_ 1366 100;
BA_ "GenMsgCycleTime" BO_ 1365 100;
BA_ "GenMsgCycleTimeFast" BO_ 1365 100;
BA_ "GenMsgCycleTime" BO_ 786 100;
BA_ "GenMsgCycleTimeFast" BO_ 786 100;
BA_ "GenMsgCycleTime" BO_ 1364 100;
BA_ "GenMsgCycleTimeFast" BO_ 1364 100;
BA_ "GenMsgCycleTime" BO_ 1363 100;
BA_ "GenMsgCycleTimeFast" BO_ 1363 100;
BA_ "GenMsgCycleTime" BO_ 1362 100;
BA_ "GenMsgCycleTimeFast" BO_ 1362 100;
BA_ "GenMsgCycleTime" BO_ 1361 100;
BA_ "GenMsgCycleTimeFast" BO_ 1361 100;
BA_ "GenMsgCycleTime" BO_ 1360 100;
BA_ "GenMsgCycleTimeFast" BO_ 1360 100;
BA_ "GenMsgCycleTime" BO_ 1359 100;
BA_ "GenMsgCycleTimeFast" BO_ 1359 100;
BA_ "GenMsgCycleTime" BO_ 1358 100;
BA_ "GenMsgCycleTimeFast" BO_ 1358 100;
BA_ "GenMsgCycleTime" BO_ 1357 100;
BA_ "GenMsgCycleTimeFast" BO_ 1357 100;
BA_ "GenMsgCycleTime" BO_ 1356 100;
BA_ "GenMsgCycleTimeFast" BO_ 1356 100;
BA_ "GenMsgCycleTime" BO_ 1355 100;
BA_ "GenMsgCycleTimeFast" BO_ 1355 100;
BA_ "GenMsgCycleTime" BO_ 1354 100;
BA_ "GenMsgCycleTimeFast" BO_ 1354 100;
BA_ "GenMsgCycleTime" BO_ 1353 100;
BA_ "GenMsgCycleTimeFast" BO_ 1353 100;
BA_ "GenMsgCycleTime" BO_ 1352 100;
BA_ "GenMsgCycleTimeFast" BO_ 1352 100;
BA_ "GenMsgCycleTime" BO_ 1351 100;
BA_ "GenMsgCycleTimeFast" BO_ 1351 100;
BA_ "GenMsgCycleTime" BO_ 1350 100;
BA_ "GenMsgCycleTimeFast" BO_ 1350 100;
BA_ "GenMsgCycleTime" BO_ 1349 100;
BA_ "GenMsgCycleTimeFast" BO_ 1349 100;
BA_ "GenMsgCycleTime" BO_ 1348 100;
BA_ "GenMsgCycleTimeFast" BO_ 1348 100;
BA_ "GenMsgCycleTime" BO_ 1347 100;
BA_ "GenMsgCycleTimeFast" BO_ 1347 100;
BA_ "GenMsgCycleTime" BO_ 1346 100;
BA_ "GenMsgCycleTimeFast" BO_ 1346 100;
BA_ "GenMsgCycleTime" BO_ 1345 100;
BA_ "GenMsgCycleTimeFast" BO_ 1345 100;
BA_ "GenMsgCycleTime" BO_ 1344 100;
BA_ "GenMsgCycleTimeFast" BO_ 1344 100;
BA_ "GenMsgCycleTime" BO_ 1343 100;
BA_ "GenMsgCycleTimeFast" BO_ 1343 100;
BA_ "GenMsgCycleTime" BO_ 1342 100;
BA_ "GenMsgCycleTimeFast" BO_ 1342 100;
BA_ "GenMsgCycleTime" BO_ 1341 100;
BA_ "GenMsgCycleTimeFast" BO_ 1341 100;
BA_ "GenMsgCycleTime" BO_ 1340 100;
BA_ "GenMsgCycleTimeFast" BO_ 1340 100;
BA_ "GenMsgCycleTime" BO_ 1339 100;
BA_ "GenMsgCycleTimeFast" BO_ 1339 100;
BA_ "GenMsgCycleTime" BO_ 1338 100;
BA_ "GenMsgCycleTimeFast" BO_ 1338 100;
BA_ "GenMsgCycleTime" BO_ 1337 100;
BA_ "GenMsgCycleTimeFast" BO_ 1337 100;
BA_ "GenMsgCycleTime" BO_ 1336 100;
BA_ "GenMsgCycleTimeFast" BO_ 1336 100;
BA_ "GenMsgCycleTime" BO_ 1335 100;
BA_ "GenMsgCycleTimeFast" BO_ 1335 100;
BA_ "GenMsgCycleTime" BO_ 781 100;
BA_ "GenMsgCycleTimeFast" BO_ 781 100;
BA_ "GenMsgCycleTime" BO_ 1334 100;
BA_ "GenMsgCycleTimeFast" BO_ 1334 100;
BA_ "GenMsgCycleTime" BO_ 1333 100;
BA_ "GenMsgCycleTimeFast" BO_ 1333 100;
BA_ "GenMsgCycleTime" BO_ 1332 100;
BA_ "GenMsgCycleTimeFast" BO_ 1332 100;
BA_ "GenMsgCycleTime" BO_ 1331 100;
BA_ "GenMsgCycleTimeFast" BO_ 1331 100;
BA_ "GenMsgCycleTime" BO_ 1330 100;
BA_ "GenMsgCycleTimeFast" BO_ 1330 100;
BA_ "GenMsgCycleTime" BO_ 1329 100;
BA_ "GenMsgCycleTimeFast" BO_ 1329 100;
BA_ "GenMsgCycleTime" BO_ 1328 100;
BA_ "GenMsgCycleTimeFast" BO_ 1328 100;
BA_ "GenMsgCycleTime" BO_ 1327 100;
BA_ "GenMsgCycleTimeFast" BO_ 1327 100;
BA_ "GenMsgCycleTime" BO_ 1326 100;
BA_ "GenMsgCycleTimeFast" BO_ 1326 100;
BA_ "GenMsgCycleTime" BO_ 1325 100;
BA_ "GenMsgCycleTimeFast" BO_ 1325 100;
BA_ "GenMsgCycleTime" BO_ 780 100;
BA_ "GenMsgCycleTimeFast" BO_ 780 100;
BA_ "GenMsgCycleTime" BO_ 1324 100;
BA_ "GenMsgCycleTimeFast" BO_ 1324 100;
BA_ "GenSigCycleTime" SG_ 1091 VCUStoredBeltWarningLightSC 200;
BA_ "GenSigCycleTimeActive" SG_ 1091 VCUStoredBeltWarningLightSC 200;
BA_ "GenSigCycleTime" SG_ 1091 VCUStoredLowSOCSC 200;
BA_ "GenSigCycleTimeActive" SG_ 1091 VCUStoredLowSOCSC 200;
BA_ "GenSigCycleTime" SG_ 1091 VCUStoredRearSeatBuckle2LightSC 200;
BA_ "GenSigCycleTimeActive" SG_ 1091 VCUStoredRearSeatBuckle2LightSC 200;
BA_ "GenSigCycleTime" SG_ 1091 VCUStoredReverseLightSC 200;
BA_ "GenSigCycleTimeActive" SG_ 1091 VCUStoredReverseLightSC 200;
BA_ "GenSigCycleTime" SG_ 1091 VCUStoredRadioMuteSC 200;
BA_ "GenSigCycleTimeActive" SG_ 1091 VCUStoredRadioMuteSC 200;
BA_ "GenSigCycleTime" SG_ 1091 VCUStoredIllumOutputSC 200;
BA_ "GenSigCycleTimeActive" SG_ 1091 VCUStoredIllumOutputSC 200;
BA_ "GenSigCycleTime" SG_ 1091 VCUStoredNeutralLightSC 200;
BA_ "GenSigCycleTimeActive" SG_ 1091 VCUStoredNeutralLightSC 200;
BA_ "GenSigCycleTime" SG_ 1091 VCUStoredDriveEnableLightSC 200;
BA_ "GenSigCycleTimeActive" SG_ 1091 VCUStoredDriveEnableLightSC 200;
BA_ "GenSigCycleTime" SG_ 1091 VCUStoredOvertempLightSC 200;
BA_ "GenSigCycleTimeActive" SG_ 1091 VCUStoredOvertempLightSC 200;
BA_ "GenSigCycleTime" SG_ 1091 VCUStoredIndicationBarSupplySC 200;
BA_ "GenSigCycleTimeActive" SG_ 1091 VCUStoredIndicationBarSupplySC 200;
BA_ "GenSigCycleTime" SG_ 1091 VCUStoredPowerLimitLightSC 200;
BA_ "GenSigCycleTimeActive" SG_ 1091 VCUStoredPowerLimitLightSC 200;
BA_ "GenSigCycleTime" SG_ 1091 VCUStoredTransceiverTXSC 200;
BA_ "GenSigCycleTimeActive" SG_ 1091 VCUStoredTransceiverTXSC 200;
BA_ "GenSigCycleTime" SG_ 1091 VCUStoredElHazardLightSC 200;
BA_ "GenSigCycleTimeActive" SG_ 1091 VCUStoredElHazardLightSC 200;
BA_ "GenSigCycleTime" SG_ 1091 VCUStoredBrakeWarningLightSC 200;
BA_ "GenSigCycleTimeActive" SG_ 1091 VCUStoredBrakeWarningLightSC 200;
BA_ "GenSigCycleTime" SG_ 1091 VCUStoredEconomyGaugeSC 200;
BA_ "GenSigCycleTimeActive" SG_ 1091 VCUStoredEconomyGaugeSC 200;
BA_ "GenSigCycleTime" SG_ 1091 VCUStoredTransceiverSupplySC 200;
BA_ "GenSigCycleTimeActive" SG_ 1091 VCUStoredTransceiverSupplySC 200;
BA_ "GenSigCycleTime" SG_ 1091 VCUStoredDischargeRequestSC 200;
BA_ "GenSigCycleTimeActive" SG_ 1091 VCUStoredDischargeRequestSC 200;
BA_ "GenSigCycleTime" SG_ 1091 VCUStoredCrashLineSC 200;
BA_ "GenSigCycleTimeActive" SG_ 1091 VCUStoredCrashLineSC 200;
BA_ "GenSigCycleTime" SG_ 1091 VCUStoredABSWarningLightSC 200;
BA_ "GenSigCycleTimeActive" SG_ 1091 VCUStoredABSWarningLightSC 200;
BA_ "GenSigCycleTime" SG_ 1091 VCUStoredImmoLightSC 200;
BA_ "GenSigCycleTimeActive" SG_ 1091 VCUStoredImmoLightSC 200;
BA_ "GenSigCycleTime" SG_ 1091 VCUStoredDriveLightSC 200;
BA_ "GenSigCycleTimeActive" SG_ 1091 VCUStoredDriveLightSC 200;
BA_ "GenSigCycleTime" SG_ 1091 VCUStoredAuxBattLowLightSC 200;
BA_ "GenSigCycleTimeActive" SG_ 1091 VCUStoredAuxBattLowLightSC 200;
BA_ "GenSigCycleTime" SG_ 1091 VCUStoredChargeLightSC 200;
BA_ "GenSigCycleTimeActive" SG_ 1091 VCUStoredChargeLightSC 200;
BA_ "GenSigCycleTime" SG_ 1091 VCUStoredTPMSLightSC 200;
BA_ "GenSigCycleTimeActive" SG_ 1091 VCUStoredTPMSLightSC 200;
BA_ "GenSigCycleTime" SG_ 1091 VCUStoredSpeedGaugeSC 200;
BA_ "GenSigCycleTimeActive" SG_ 1091 VCUStoredSpeedGaugeSC 200;
BA_ "GenSigCycleTime" SG_ 1091 VCUStoredEconomyLightSC 200;
BA_ "GenSigCycleTimeActive" SG_ 1091 VCUStoredEconomyLightSC 200;
BA_ "GenSigCycleTime" SG_ 1091 VCUStoredOnPlugLightSC 200;
BA_ "GenSigCycleTimeActive" SG_ 1091 VCUStoredOnPlugLightSC 200;
BA_ "GenSigCycleTime" SG_ 1091 VCUStoredChimeLineSC 200;
BA_ "GenSigCycleTimeActive" SG_ 1091 VCUStoredChimeLineSC 200;
BA_ "GenSigCycleTime" SG_ 1091 VCUStoredESPLightSC 200;
BA_ "GenSigCycleTimeActive" SG_ 1091 VCUStoredESPLightSC 200;
BA_ "GenSigCycleTime" SG_ 1091 VCUStoredSOCGaugeSC 200;
BA_ "GenSigCycleTimeActive" SG_ 1091 VCUStoredSOCGaugeSC 200;
BA_ "GenSigCycleTime" SG_ 1091 VCUStoredMILLightSC 200;
BA_ "GenSigCycleTimeActive" SG_ 1091 VCUStoredMILLightSC 200;
BA_ "GenSigCycleTime" SG_ 1091 VCUStoredParkLightSC 200;
BA_ "GenSigCycleTimeActive" SG_ 1091 VCUStoredParkLightSC 200;
BA_ "GenSigCycleTime" SG_ 1091 VCUStoredAirbagLightSC 200;
BA_ "GenSigCycleTimeActive" SG_ 1091 VCUStoredAirbagLightSC 200;
BA_ "GenSigCycleTime" SG_ 1091 VCUStoredIgnitionSpeedSC 200;
BA_ "GenSigCycleTimeActive" SG_ 1091 VCUStoredIgnitionSpeedSC 200;
BA_ "GenSigCycleTime" SG_ 1091 VCUStoredRearSeatBuckle1LightSC 200;
BA_ "GenSigCycleTimeActive" SG_ 1091 VCUStoredRearSeatBuckle1LightSC 200;
BA_ "GenSigCycleTime" SG_ 1092 VCUStoredImmoLightOC 200;
BA_ "GenSigCycleTimeActive" SG_ 1092 VCUStoredImmoLightOC 200;
BA_ "GenSigCycleTime" SG_ 1092 VCUStoredReverseLightOC 200;
BA_ "GenSigCycleTimeActive" SG_ 1092 VCUStoredReverseLightOC 200;
BA_ "GenSigCycleTime" SG_ 1092 VCUStoredDischargeRequestOC 200;
BA_ "GenSigCycleTimeActive" SG_ 1092 VCUStoredDischargeRequestOC 200;
BA_ "GenSigCycleTime" SG_ 1092 VCUStoredPowerLimitLightOC 200;
BA_ "GenSigCycleTimeActive" SG_ 1092 VCUStoredPowerLimitLightOC 200;
BA_ "GenSigCycleTime" SG_ 1092 VCUStoredRearSeatBuckle1LightOC 200;
BA_ "GenSigCycleTimeActive" SG_ 1092 VCUStoredRearSeatBuckle1LightOC 200;
BA_ "GenSigCycleTime" SG_ 1092 VCUStoredTPMSLightOC 200;
BA_ "GenSigCycleTimeActive" SG_ 1092 VCUStoredTPMSLightOC 200;
BA_ "GenSigCycleTime" SG_ 1092 VCUStoredOvertempLightOC 200;
BA_ "GenSigCycleTimeActive" SG_ 1092 VCUStoredOvertempLightOC 200;
BA_ "GenSigCycleTime" SG_ 1092 VCUStoredSOCGaugeOC 200;
BA_ "GenSigCycleTimeActive" SG_ 1092 VCUStoredSOCGaugeOC 200;
BA_ "GenSigCycleTime" SG_ 1092 VCUStoredESPLightOC 200;
BA_ "GenSigCycleTimeActive" SG_ 1092 VCUStoredESPLightOC 200;
BA_ "GenSigCycleTime" SG_ 1092 VCUStoredCrashLineOC 200;
BA_ "GenSigCycleTimeActive" SG_ 1092 VCUStoredCrashLineOC 200;
BA_ "GenSigCycleTime" SG_ 1092 VCUStoredIndicationBarSupplyOC 200;
BA_ "GenSigCycleTimeActive" SG_ 1092 VCUStoredIndicationBarSupplyOC 200;
BA_ "GenSigCycleTime" SG_ 1092 VCUStoredEconomyLightOC 200;
BA_ "GenSigCycleTimeActive" SG_ 1092 VCUStoredEconomyLightOC 200;
BA_ "GenSigCycleTime" SG_ 1092 VCUStoredAirbagLightOC 200;
BA_ "GenSigCycleTimeActive" SG_ 1092 VCUStoredAirbagLightOC 200;
BA_ "GenSigCycleTime" SG_ 1092 VCUStoredEconomyGaugeOC 200;
BA_ "GenSigCycleTimeActive" SG_ 1092 VCUStoredEconomyGaugeOC 200;
BA_ "GenSigCycleTime" SG_ 1092 VCUStoredTransceiverSupplyOC 200;
BA_ "GenSigCycleTimeActive" SG_ 1092 VCUStoredTransceiverSupplyOC 200;
BA_ "GenSigCycleTime" SG_ 1092 VCUStoredDriveLightOC 200;
BA_ "GenSigCycleTimeActive" SG_ 1092 VCUStoredDriveLightOC 200;
BA_ "GenSigCycleTime" SG_ 1092 VCUStoredAuxBattLowLightOC 200;
BA_ "GenSigCycleTimeActive" SG_ 1092 VCUStoredAuxBattLowLightOC 200;
BA_ "GenSigCycleTime" SG_ 1092 VCUStoredRearSeatBuckle2LightOC 200;
BA_ "GenSigCycleTimeActive" SG_ 1092 VCUStoredRearSeatBuckle2LightOC 200;
BA_ "GenSigCycleTime" SG_ 1092 VCUStoredIgnitionSpeedOC 200;
BA_ "GenSigCycleTimeActive" SG_ 1092 VCUStoredIgnitionSpeedOC 200;
BA_ "GenSigCycleTime" SG_ 1092 VCUStoredMILLightOC 200;
BA_ "GenSigCycleTimeActive" SG_ 1092 VCUStoredMILLightOC 200;
BA_ "GenSigCycleTime" SG_ 1092 VCUStoredChimeLineOC 200;
BA_ "GenSigCycleTimeActive" SG_ 1092 VCUStoredChimeLineOC 200;
BA_ "GenSigCycleTime" SG_ 1092 VCUStoredDriveEnableLightOC 200;
BA_ "GenSigCycleTimeActive" SG_ 1092 VCUStoredDriveEnableLightOC 200;
BA_ "GenSigCycleTime" SG_ 1092 VCUStoredLowSOCOC 200;
BA_ "GenSigCycleTimeActive" SG_ 1092 VCUStoredLowSOCOC 200;
BA_ "GenSigCycleTime" SG_ 1092 VCUStoredElHazardLightOC 200;
BA_ "GenSigCycleTimeActive" SG_ 1092 VCUStoredElHazardLightOC 200;
BA_ "GenSigCycleTime" SG_ 1092 VCUStoredBrakeWarningLightOC 200;
BA_ "GenSigCycleTimeActive" SG_ 1092 VCUStoredBrakeWarningLightOC 200;
BA_ "GenSigCycleTime" SG_ 1092 VCUStoredIllumOutputOC 200;
BA_ "GenSigCycleTimeActive" SG_ 1092 VCUStoredIllumOutputOC 200;
BA_ "GenSigCycleTime" SG_ 1092 VCUStoredABSWarningLightOC 200;
BA_ "GenSigCycleTimeActive" SG_ 1092 VCUStoredABSWarningLightOC 200;
BA_ "GenSigCycleTime" SG_ 1092 VCUStoredTransceiverTXOC 200;
BA_ "GenSigCycleTimeActive" SG_ 1092 VCUStoredTransceiverTXOC 200;
BA_ "GenSigCycleTime" SG_ 1092 VCUStoredBeltWarningLightOC 200;
BA_ "GenSigCycleTimeActive" SG_ 1092 VCUStoredBeltWarningLightOC 200;
BA_ "GenSigCycleTime" SG_ 1092 VCUStoredSpeedGaugeOC 200;
BA_ "GenSigCycleTimeActive" SG_ 1092 VCUStoredSpeedGaugeOC 200;
BA_ "GenSigCycleTime" SG_ 1092 VCUStoredRadioMuteOC 200;
BA_ "GenSigCycleTimeActive" SG_ 1092 VCUStoredRadioMuteOC 200;
BA_ "GenSigCycleTime" SG_ 1092 VCUStoredParkLightOC 200;
BA_ "GenSigCycleTimeActive" SG_ 1092 VCUStoredParkLightOC 200;
BA_ "GenSigCycleTime" SG_ 1092 VCUStoredNeutralLightOC 200;
BA_ "GenSigCycleTimeActive" SG_ 1092 VCUStoredNeutralLightOC 200;
BA_ "GenSigCycleTime" SG_ 1092 VCUStoredChargeLightOC 200;
BA_ "GenSigCycleTimeActive" SG_ 1092 VCUStoredChargeLightOC 200;
BA_ "GenSigCycleTime" SG_ 1092 VCUStoredOnPlugLightOC 200;
BA_ "GenSigCycleTimeActive" SG_ 1092 VCUStoredOnPlugLightOC 200;
BA_ "GenSigCycleTime" SG_ 1088 TPMSButtonLearnActivation 200;
BA_ "GenSigCycleTimeActive" SG_ 1088 TPMSButtonLearnActivation 200;
BA_ "GenSigCycleTime" SG_ 1088 VCUSWYear 200;
BA_ "GenSigCycleTimeActive" SG_ 1088 VCUSWYear 200;
BA_ "GenSigCycleTime" SG_ 1088 VCUSWVersion 200;
BA_ "GenSigCycleTimeActive" SG_ 1088 VCUSWVersion 200;
BA_ "GenSigCycleTime" SG_ 1088 VCUSWDay 200;
BA_ "GenSigCycleTimeActive" SG_ 1088 VCUSWDay 200;
BA_ "GenSigCycleTime" SG_ 1088 VCUSWMonth 200;
BA_ "GenSigCycleTimeActive" SG_ 1088 VCUSWMonth 200;
BA_ "GenSigCycleTime" SG_ 1088 VCUPTCReady 200;
BA_ "GenSigCycleTimeActive" SG_ 1088 VCUPTCReady 200;
BA_ "GenSigCycleTime" SG_ 1089 VCUPresentMILLightSC 200;
BA_ "GenSigCycleTimeActive" SG_ 1089 VCUPresentMILLightSC 200;
BA_ "GenSigCycleTime" SG_ 1089 VCUPresentImmoLightSC 200;
BA_ "GenSigCycleTimeActive" SG_ 1089 VCUPresentImmoLightSC 200;
BA_ "GenSigCycleTime" SG_ 1089 VCUPresentEconomyLightSC 200;
BA_ "GenSigCycleTimeActive" SG_ 1089 VCUPresentEconomyLightSC 200;
BA_ "GenSigCycleTime" SG_ 1089 VCUPresentTransceiverSupplySC 200;
BA_ "GenSigCycleTimeActive" SG_ 1089 VCUPresentTransceiverSupplySC 200;
BA_ "GenSigCycleTime" SG_ 1089 VCUPresentIgnitionSpeedSC 200;
BA_ "GenSigCycleTimeActive" SG_ 1089 VCUPresentIgnitionSpeedSC 200;
BA_ "GenSigCycleTime" SG_ 1089 VCUPresentChimeLineSC 200;
BA_ "GenSigCycleTimeActive" SG_ 1089 VCUPresentChimeLineSC 200;
BA_ "GenSigCycleTime" SG_ 1089 VCUPresentElHazardLightSC 200;
BA_ "GenSigCycleTimeActive" SG_ 1089 VCUPresentElHazardLightSC 200;
BA_ "GenSigCycleTime" SG_ 1089 VCUPresentBrakeWarningLightSC 200;
BA_ "GenSigCycleTimeActive" SG_ 1089 VCUPresentBrakeWarningLightSC 200;
BA_ "GenSigCycleTime" SG_ 1089 VCUPresentRadioMuteSC 200;
BA_ "GenSigCycleTimeActive" SG_ 1089 VCUPresentRadioMuteSC 200;
BA_ "GenSigCycleTime" SG_ 1089 VCUPresentSOCGaugeSC 200;
BA_ "GenSigCycleTimeActive" SG_ 1089 VCUPresentSOCGaugeSC 200;
BA_ "GenSigCycleTime" SG_ 1089 VCUPresentNeutralLightSC 200;
BA_ "GenSigCycleTimeActive" SG_ 1089 VCUPresentNeutralLightSC 200;
BA_ "GenSigCycleTime" SG_ 1089 VCUPresentParkLightSC 200;
BA_ "GenSigCycleTimeActive" SG_ 1089 VCUPresentParkLightSC 200;
BA_ "GenSigCycleTime" SG_ 1089 VCUPresentChargeLightSC 200;
BA_ "GenSigCycleTimeActive" SG_ 1089 VCUPresentChargeLightSC 200;
BA_ "GenSigCycleTime" SG_ 1089 VCUPresentEconomyGaugeSC 200;
BA_ "GenSigCycleTimeActive" SG_ 1089 VCUPresentEconomyGaugeSC 200;
BA_ "GenSigCycleTime" SG_ 1089 VCUPresentCrashLineSC 200;
BA_ "GenSigCycleTimeActive" SG_ 1089 VCUPresentCrashLineSC 200;
BA_ "GenSigCycleTime" SG_ 1089 VCUPresentESPLightSC 200;
BA_ "GenSigCycleTimeActive" SG_ 1089 VCUPresentESPLightSC 200;
BA_ "GenSigCycleTime" SG_ 1089 VCUPresentTransceiverTXSC 200;
BA_ "GenSigCycleTimeActive" SG_ 1089 VCUPresentTransceiverTXSC 200;
BA_ "GenSigCycleTime" SG_ 1089 VCUPresentReverseLightSC 200;
BA_ "GenSigCycleTimeActive" SG_ 1089 VCUPresentReverseLightSC 200;
BA_ "GenSigCycleTime" SG_ 1089 VCUPresentAirbagLightSC 200;
BA_ "GenSigCycleTimeActive" SG_ 1089 VCUPresentAirbagLightSC 200;
BA_ "GenSigCycleTime" SG_ 1089 VCUPresentIndicationBarSupplySC 200;
BA_ "GenSigCycleTimeActive" SG_ 1089 VCUPresentIndicationBarSupplySC 200;
BA_ "GenSigCycleTime" SG_ 1089 VCUPresentDriveLightSC 200;
BA_ "GenSigCycleTimeActive" SG_ 1089 VCUPresentDriveLightSC 200;
BA_ "GenSigCycleTime" SG_ 1089 VCUPresentRearSeatBuckle1LightSC 200;
BA_ "GenSigCycleTimeActive" SG_ 1089 VCUPresentRearSeatBuckle1LightSC 200;
BA_ "GenSigCycleTime" SG_ 1089 VCUPresentDischargeRequestSC 200;
BA_ "GenSigCycleTimeActive" SG_ 1089 VCUPresentDischargeRequestSC 200;
BA_ "GenSigCycleTime" SG_ 1089 VCUPresentAuxBattLowLightSC 200;
BA_ "GenSigCycleTimeActive" SG_ 1089 VCUPresentAuxBattLowLightSC 200;
BA_ "GenSigCycleTime" SG_ 1089 VCUPresentDriveEnableLightSC 200;
BA_ "GenSigCycleTimeActive" SG_ 1089 VCUPresentDriveEnableLightSC 200;
BA_ "GenSigCycleTime" SG_ 1089 VCUPresentLowSOCSC 200;
BA_ "GenSigCycleTimeActive" SG_ 1089 VCUPresentLowSOCSC 200;
BA_ "GenSigCycleTime" SG_ 1089 VCUPresentBeltWarningLightSC 200;
BA_ "GenSigCycleTimeActive" SG_ 1089 VCUPresentBeltWarningLightSC 200;
BA_ "GenSigCycleTime" SG_ 1089 VCUPresentSpeedGaugeSC 200;
BA_ "GenSigCycleTimeActive" SG_ 1089 VCUPresentSpeedGaugeSC 200;
BA_ "GenSigCycleTime" SG_ 1089 VCUPresentABSWarningLightSC 200;
BA_ "GenSigCycleTimeActive" SG_ 1089 VCUPresentABSWarningLightSC 200;
BA_ "GenSigCycleTime" SG_ 1089 VCUPresentOvertempLightSC 200;
BA_ "GenSigCycleTimeActive" SG_ 1089 VCUPresentOvertempLightSC 200;
BA_ "GenSigCycleTime" SG_ 1089 VCUPresentOnPlugLightSC 200;
BA_ "GenSigCycleTimeActive" SG_ 1089 VCUPresentOnPlugLightSC 200;
BA_ "GenSigCycleTime" SG_ 1089 VCUPresentIllumOutputSC 200;
BA_ "GenSigCycleTimeActive" SG_ 1089 VCUPresentIllumOutputSC 200;
BA_ "GenSigCycleTime" SG_ 1089 VCUPresentPowerLimitLightSC 200;
BA_ "GenSigCycleTimeActive" SG_ 1089 VCUPresentPowerLimitLightSC 200;
BA_ "GenSigCycleTime" SG_ 1089 VCUPresentTPMSLightSC 200;
BA_ "GenSigCycleTimeActive" SG_ 1089 VCUPresentTPMSLightSC 200;
BA_ "GenSigCycleTime" SG_ 1089 VCUPresentRearSeatBuckle2LightSC 200;
BA_ "GenSigCycleTimeActive" SG_ 1089 VCUPresentRearSeatBuckle2LightSC 200;
BA_ "GenSigCycleTime" SG_ 1090 VCUPresentIndicationBarSupplyOC 200;
BA_ "GenSigCycleTimeActive" SG_ 1090 VCUPresentIndicationBarSupplyOC 200;
BA_ "GenSigCycleTime" SG_ 1090 VCUPresentLowSOCOC 200;
BA_ "GenSigCycleTimeActive" SG_ 1090 VCUPresentLowSOCOC 200;
BA_ "GenSigCycleTime" SG_ 1090 VCUPresentOvertempLightOC 200;
BA_ "GenSigCycleTimeActive" SG_ 1090 VCUPresentOvertempLightOC 200;
BA_ "GenSigCycleTime" SG_ 1090 VCUPresentEconomyLightOC 200;
BA_ "GenSigCycleTimeActive" SG_ 1090 VCUPresentEconomyLightOC 200;
BA_ "GenSigCycleTime" SG_ 1090 VCUPresentParkLightOC 200;
BA_ "GenSigCycleTimeActive" SG_ 1090 VCUPresentParkLightOC 200;
BA_ "GenSigCycleTime" SG_ 1090 VCUPresentRadioMuteOC 200;
BA_ "GenSigCycleTimeActive" SG_ 1090 VCUPresentRadioMuteOC 200;
BA_ "GenSigCycleTime" SG_ 1090 VCUPresentElHazardLightOC 200;
BA_ "GenSigCycleTimeActive" SG_ 1090 VCUPresentElHazardLightOC 200;
BA_ "GenSigCycleTime" SG_ 1090 VCUPresentBeltWarningLightOC 200;
BA_ "GenSigCycleTimeActive" SG_ 1090 VCUPresentBeltWarningLightOC 200;
BA_ "GenSigCycleTime" SG_ 1090 VCUPresentDriveEnableLightOC 200;
BA_ "GenSigCycleTimeActive" SG_ 1090 VCUPresentDriveEnableLightOC 200;
BA_ "GenSigCycleTime" SG_ 1090 VCUPresentImmoLightOC 200;
BA_ "GenSigCycleTimeActive" SG_ 1090 VCUPresentImmoLightOC 200;
BA_ "GenSigCycleTime" SG_ 1090 VCUPresentAirbagLightOC 200;
BA_ "GenSigCycleTimeActive" SG_ 1090 VCUPresentAirbagLightOC 200;
BA_ "GenSigCycleTime" SG_ 1090 VCUPresentSOCGaugeOC 200;
BA_ "GenSigCycleTimeActive" SG_ 1090 VCUPresentSOCGaugeOC 200;
BA_ "GenSigCycleTime" SG_ 1090 VCUPresentSpeedGaugeOC 200;
BA_ "GenSigCycleTimeActive" SG_ 1090 VCUPresentSpeedGaugeOC 200;
BA_ "GenSigCycleTime" SG_ 1090 VCUPresentRearSeatBuckle2LightOC 200;
BA_ "GenSigCycleTimeActive" SG_ 1090 VCUPresentRearSeatBuckle2LightOC 200;
BA_ "GenSigCycleTime" SG_ 1090 VCUPresentReverseLightOC 200;
BA_ "GenSigCycleTimeActive" SG_ 1090 VCUPresentReverseLightOC 200;
BA_ "GenSigCycleTime" SG_ 1090 VCUPresentIllumOutputOC 200;
BA_ "GenSigCycleTimeActive" SG_ 1090 VCUPresentIllumOutputOC 200;
BA_ "GenSigCycleTime" SG_ 1090 VCUPresentBrakeWarningLightOC 200;
BA_ "GenSigCycleTimeActive" SG_ 1090 VCUPresentBrakeWarningLightOC 200;
BA_ "GenSigCycleTime" SG_ 1090 VCUPresentTransceiverSupplyOC 200;
BA_ "GenSigCycleTimeActive" SG_ 1090 VCUPresentTransceiverSupplyOC 200;
BA_ "GenSigCycleTime" SG_ 1090 VCUPresentABSWarningLightOC 200;
BA_ "GenSigCycleTimeActive" SG_ 1090 VCUPresentABSWarningLightOC 200;
BA_ "GenSigCycleTime" SG_ 1090 VCUPresentTransceiverTXOC 200;
BA_ "GenSigCycleTimeActive" SG_ 1090 VCUPresentTransceiverTXOC 200;
BA_ "GenSigCycleTime" SG_ 1090 VCUPresentDriveLightOC 200;
BA_ "GenSigCycleTimeActive" SG_ 1090 VCUPresentDriveLightOC 200;
BA_ "GenSigCycleTime" SG_ 1090 VCUPresentPowerLimitLightOC 200;
BA_ "GenSigCycleTimeActive" SG_ 1090 VCUPresentPowerLimitLightOC 200;
BA_ "GenSigCycleTime" SG_ 1090 VCUPresentCrashLineOC 200;
BA_ "GenSigCycleTimeActive" SG_ 1090 VCUPresentCrashLineOC 200;
BA_ "GenSigCycleTime" SG_ 1090 VCUPresentIgnitionSpeedOC 200;
BA_ "GenSigCycleTimeActive" SG_ 1090 VCUPresentIgnitionSpeedOC 200;
BA_ "GenSigCycleTime" SG_ 1090 VCUPresentAuxBattLowLightOC 200;
BA_ "GenSigCycleTimeActive" SG_ 1090 VCUPresentAuxBattLowLightOC 200;
BA_ "GenSigCycleTime" SG_ 1090 VCUPresentChargeLightOC 200;
BA_ "GenSigCycleTimeActive" SG_ 1090 VCUPresentChargeLightOC 200;
BA_ "GenSigCycleTime" SG_ 1090 VCUPresentOnPlugLightOC 200;
BA_ "GenSigCycleTimeActive" SG_ 1090 VCUPresentOnPlugLightOC 200;
BA_ "GenSigCycleTime" SG_ 1090 VCUPresentNeutralLightOC 200;
BA_ "GenSigCycleTimeActive" SG_ 1090 VCUPresentNeutralLightOC 200;
BA_ "GenSigCycleTime" SG_ 1090 VCUPresentEconomyGaugeOC 200;
BA_ "GenSigCycleTimeActive" SG_ 1090 VCUPresentEconomyGaugeOC 200;
BA_ "GenSigCycleTime" SG_ 1090 VCUPresentChimeLineOC 200;
BA_ "GenSigCycleTimeActive" SG_ 1090 VCUPresentChimeLineOC 200;
BA_ "GenSigCycleTime" SG_ 1090 VCUPresentRearSeatBuckle1LightOC 200;
BA_ "GenSigCycleTimeActive" SG_ 1090 VCUPresentRearSeatBuckle1LightOC 200;
BA_ "GenSigCycleTime" SG_ 1090 VCUPresentESPLightOC 200;
BA_ "GenSigCycleTimeActive" SG_ 1090 VCUPresentESPLightOC 200;
BA_ "GenSigCycleTime" SG_ 1090 VCUPresentTPMSLightOC 200;
BA_ "GenSigCycleTimeActive" SG_ 1090 VCUPresentTPMSLightOC 200;
BA_ "GenSigCycleTime" SG_ 1090 VCUPresentDischargeRequestOC 200;
BA_ "GenSigCycleTimeActive" SG_ 1090 VCUPresentDischargeRequestOC 200;
BA_ "GenSigCycleTime" SG_ 1090 VCUPresentMILLightOC 200;
BA_ "GenSigCycleTimeActive" SG_ 1090 VCUPresentMILLightOC 200;
BA_ "GenSigCycleTime" SG_ 929 WarningLightTemperatureActivated 500;
BA_ "GenSigCycleTimeActive" SG_ 929 WarningLightTemperatureActivated 500;
BA_ "GenSigCycleTime" SG_ 929 WarningLightAirbagActivated 500;
BA_ "GenSigCycleTimeActive" SG_ 929 WarningLightAirbagActivated 500;
BA_ "GenSigCycleTime" SG_ 929 OnPlugBatteryTemperatureControl 500;
BA_ "GenSigCycleTimeActive" SG_ 929 OnPlugBatteryTemperatureControl 500;
BA_ "GenSigCycleTime" SG_ 929 OnPlugPCUChargeEnabled 500;
BA_ "GenSigCycleTimeActive" SG_ 929 OnPlugPCUChargeEnabled 500;
BA_ "GenSigCycleTime" SG_ 929 KeyOnEPOBroken 500;
BA_ "GenSigCycleTimeActive" SG_ 929 KeyOnEPOBroken 500;
BA_ "GenSigCycleTime" SG_ 929 OnPlugFullChargeRequested 500;
BA_ "GenSigCycleTimeActive" SG_ 929 OnPlugFullChargeRequested 500;
BA_ "GenSigCycleTime" SG_ 929 WarningLightTPMSActivated 500;
BA_ "GenSigCycleTimeActive" SG_ 929 WarningLightTPMSActivated 500;
BA_ "GenSigCycleTime" SG_ 929 KeyOnTractionEnabled 500;
BA_ "GenSigCycleTimeActive" SG_ 929 KeyOnTractionEnabled 500;
BA_ "GenSigCycleTime" SG_ 929 WarningLightPowerLimitActivated 500;
BA_ "GenSigCycleTimeActive" SG_ 929 WarningLightPowerLimitActivated 500;
BA_ "GenSigCycleTime" SG_ 929 KeyOnImmobilizerEnabled 500;
BA_ "GenSigCycleTimeActive" SG_ 929 KeyOnImmobilizerEnabled 500;
BA_ "GenSigCycleTime" SG_ 929 ExternalTemperature 500;
BA_ "GenSigCycleTimeActive" SG_ 929 ExternalTemperature 500;
BA_ "GenSigCycleTime" SG_ 929 WarningLightESPActivated 500;
BA_ "GenSigCycleTimeActive" SG_ 929 WarningLightESPActivated 500;
BA_ "GenSigCycleTime" SG_ 929 KeyOnGearPosition 500;
BA_ "GenSigCycleTimeActive" SG_ 929 KeyOnGearPosition 500;
BA_ "GenSigCycleTime" SG_ 929 WarningLightMalfunctionActivated 500;
BA_ "GenSigCycleTimeActive" SG_ 929 WarningLightMalfunctionActivated 500;
BA_ "GenSigCycleTime" SG_ 929 WarningLightBrakeActivated 500;
BA_ "GenSigCycleTimeActive" SG_ 929 WarningLightBrakeActivated 500;
BA_ "GenSigCycleTime" SG_ 929 OnPlugEndOfCharge 500;
BA_ "GenSigCycleTimeActive" SG_ 929 OnPlugEndOfCharge 500;
BA_ "GenSigCycleTime" SG_ 929 OnPlugBatteryChargeEnabled 500;
BA_ "GenSigCycleTimeActive" SG_ 929 OnPlugBatteryChargeEnabled 500;
BA_ "GenSigCycleTime" SG_ 929 WarningLightABSActivated 500;
BA_ "GenSigCycleTimeActive" SG_ 929 WarningLightABSActivated 500;
BA_ "GenSigCycleTime" SG_ 929 NominalBatteryCapacity 500;
BA_ "GenSigCycleTimeActive" SG_ 929 NominalBatteryCapacity 500;
BA_ "GenSigCycleTime" SG_ 929 WarningLightLowSOCActivated 500;
BA_ "GenSigCycleTimeActive" SG_ 929 WarningLightLowSOCActivated 500;
BA_ "GenSigCycleTime" SG_ 929 OnPlugCharging 500;
BA_ "GenSigCycleTimeActive" SG_ 929 OnPlugCharging 500;
BA_ "GenSigCycleTime" SG_ 929 OnPlugBatteryEvaluation 500;
BA_ "GenSigCycleTimeActive" SG_ 929 OnPlugBatteryEvaluation 500;
BA_ "GenSigCycleTime" SG_ 929 KeyOnCrashDetected 500;
BA_ "GenSigCycleTimeActive" SG_ 929 KeyOnCrashDetected 500;
BA_ "GenSigCycleTime" SG_ 929 KeyOnBatteryDischargeEnabled 500;
BA_ "GenSigCycleTimeActive" SG_ 929 KeyOnBatteryDischargeEnabled 500;
BA_ "GenSigCycleTime" SG_ 929 WarningLightElHazardActivated 500;
BA_ "GenSigCycleTimeActive" SG_ 929 WarningLightElHazardActivated 500;
BA_ "GenSigCycleTime" SG_ 929 VehicleState 500;
BA_ "GenSigCycleTimeActive" SG_ 929 VehicleState 500;
BA_ "GenSigCycleTime" SG_ 929 OnPlugChargerEnabled 500;
BA_ "GenSigCycleTimeActive" SG_ 929 OnPlugChargerEnabled 500;
BA_ "GenSigCycleTime" SG_ 928 DistanceTraveledSinceStart 500;
BA_ "GenSigCycleTimeActive" SG_ 928 DistanceTraveledSinceStart 500;
BA_ "GenSigCycleTime" SG_ 928 BatteryStateOfCharge 500;
BA_ "GenSigCycleTimeActive" SG_ 928 BatteryStateOfCharge 500;
BA_ "GenSigCycleTime" SG_ 928 kWhSinceStart 500;
BA_ "GenSigCycleTimeActive" SG_ 928 kWhSinceStart 500;
BA_ "GenSigCycleTime" SG_ 928 OffboardVehicleSpeed 500;
BA_ "GenSigCycleTimeActive" SG_ 928 OffboardVehicleSpeed 500;
BA_ "GenSigCycleTime" SG_ 592 MoreThanMaxError 100;
BA_ "GenSigCycleTimeActive" SG_ 592 MoreThanMaxError 100;
BA_ "GenSigCycleTime" SG_ 592 ChallengeResponseActive 100;
BA_ "GenSigCycleTimeActive" SG_ 592 ChallengeResponseActive 100;
BA_ "GenSigCycleTime" SG_ 592 AntennaError 100;
BA_ "GenSigCycleTimeActive" SG_ 592 AntennaError 100;
BA_ "GenSigCycleTime" SG_ 592 TransponderError 100;
BA_ "GenSigCycleTimeActive" SG_ 592 TransponderError 100;
BA_ "GenSigCycleTime" SG_ 592 ChallengeMissingError 100;
BA_ "GenSigCycleTimeActive" SG_ 592 ChallengeMissingError 100;
BA_ "GenSigCycleTime" SG_ 592 PartialKeyCodeError 100;
BA_ "GenSigCycleTimeActive" SG_ 592 PartialKeyCodeError 100;
BA_ "GenSigCycleTime" SG_ 592 RequestID 100;
BA_ "GenSigCycleTimeActive" SG_ 592 RequestID 100;
BA_ "GenSigCycleTime" SG_ 592 AntiscanError 100;
BA_ "GenSigCycleTimeActive" SG_ 592 AntiscanError 100;
BA_ "GenSigCycleTime" SG_ 592 MismatchError 100;
BA_ "GenSigCycleTimeActive" SG_ 592 MismatchError 100;
BA_ "GenSigCycleTime" SG_ 592 LEDIndication 100;
BA_ "GenSigCycleTimeActive" SG_ 592 LEDIndication 100;
BA_ "GenSigCycleTime" SG_ 592 NoCommunicationError 100;
BA_ "GenSigCycleTimeActive" SG_ 592 NoCommunicationError 100;
BA_ "GenSigCycleTime" SG_ 592 KeyStatus 100;
BA_ "GenSigCycleTimeActive" SG_ 592 KeyStatus 100;
BA_ "GenSigCycleTime" SG_ 592 SecurityIDRefuseError 100;
BA_ "GenSigCycleTimeActive" SG_ 592 SecurityIDRefuseError 100;
BA_ "GenSigCycleTime" SG_ 592 LessThanMinError 100;
BA_ "GenSigCycleTimeActive" SG_ 592 LessThanMinError 100;
BA_ "GenSigCycleTime" SG_ 592 SecurityIDNotProgrammedError 100;
BA_ "GenSigCycleTimeActive" SG_ 592 SecurityIDNotProgrammedError 100;
BA_ "GenSigCycleTime" SG_ 592 SecurityIDMissingError 100;
BA_ "GenSigCycleTimeActive" SG_ 592 SecurityIDMissingError 100;
BA_ "GenSigCycleTime" SG_ 592 UnprogrammedError 100;
BA_ "GenSigCycleTimeActive" SG_ 592 UnprogrammedError 100;
BA_ "GenSigCycleTime" SG_ 592 NumberProgrammedKeys 100;
BA_ "GenSigCycleTimeActive" SG_ 592 NumberProgrammedKeys 100;
BA_ "GenSigCycleTime" SG_ 592 ChallengeResponse 100;
BA_ "GenSigCycleTimeActive" SG_ 592 ChallengeResponse 100;
BA_ "GenSigCycleTime" SG_ 836 SensorPressure_LF 200;
BA_ "GenSigCycleTimeActive" SG_ 836 SensorPressure_LF 200;
BA_ "GenSigCycleTime" SG_ 836 SensorPressure_RF 200;
BA_ "GenSigCycleTimeActive" SG_ 836 SensorPressure_RF 200;
BA_ "GenSigCycleTime" SG_ 836 SensorPressure_RR 200;
BA_ "GenSigCycleTimeActive" SG_ 836 SensorPressure_RR 200;
BA_ "GenSigCycleTime" SG_ 836 SensorPressure_LR 200;
BA_ "GenSigCycleTimeActive" SG_ 836 SensorPressure_LR 200;
BA_ "GenSigCycleTime" SG_ 837 TPMSLearnLastResult 200;
BA_ "GenSigCycleTimeActive" SG_ 837 TPMSLearnLastResult 200;
BA_ "GenSigCycleTime" SG_ 837 TPMSTelltaleControl 200;
BA_ "GenSigCycleTimeActive" SG_ 837 TPMSTelltaleControl 200;
BA_ "GenSigCycleTime" SG_ 837 TPMSWarning_RR 200;
BA_ "GenSigCycleTimeActive" SG_ 837 TPMSWarning_RR 200;
BA_ "GenSigCycleTime" SG_ 837 TPMSLearnStatus 200;
BA_ "GenSigCycleTimeActive" SG_ 837 TPMSLearnStatus 200;
BA_ "GenSigCycleTime" SG_ 837 TPMSWarning_LF 200;
BA_ "GenSigCycleTimeActive" SG_ 837 TPMSWarning_LF 200;
BA_ "GenSigCycleTime" SG_ 837 TPMSWarning_LR 200;
BA_ "GenSigCycleTimeActive" SG_ 837 TPMSWarning_LR 200;
BA_ "GenSigCycleTime" SG_ 837 TPMSWarning_RF 200;
BA_ "GenSigCycleTimeActive" SG_ 837 TPMSWarning_RF 200;
BA_ "GenSigCycleTime" SG_ 837 TPMSNumberLearnedSensors 200;
BA_ "GenSigCycleTimeActive" SG_ 837 TPMSNumberLearnedSensors 200;
VAL_ 1091 VCUStoredBeltWarningLightSC 1 "Error present" 0 "Error not present" ;
VAL_ 1091 VCUStoredLowSOCSC 1 "Error present" 0 "Error not present" ;
VAL_ 1091 VCUStoredRearSeatBuckle2LightSC 1 "Error present" 0 "Error not present" ;
VAL_ 1091 VCUStoredReverseLightSC 1 "Error present" 0 "Error not present" ;
VAL_ 1091 VCUStoredRadioMuteSC 1 "Error present" 0 "Error not present" ;
VAL_ 1091 VCUStoredIllumOutputSC 1 "Error present" 0 "Error not present" ;
VAL_ 1091 VCUStoredNeutralLightSC 1 "Error present" 0 "Error not present" ;
VAL_ 1091 VCUStoredDriveEnableLightSC 1 "Error present" 0 "Error not present" ;
VAL_ 1091 VCUStoredOvertempLightSC 1 "Error present" 0 "Error not present" ;
VAL_ 1091 VCUStoredIndicationBarSupplySC 1 "Error present" 0 "Error not present" ;
VAL_ 1091 VCUStoredPowerLimitLightSC 1 "Error present" 0 "Error not present" ;
VAL_ 1091 VCUStoredTransceiverTXSC 1 "Error present" 0 "Error not present" ;
VAL_ 1091 VCUStoredElHazardLightSC 1 "Error present" 0 "Error not present" ;
VAL_ 1091 VCUStoredBrakeWarningLightSC 1 "Error present" 0 "Error not present" ;
VAL_ 1091 VCUStoredEconomyGaugeSC 1 "Error present" 0 "Error not present" ;
VAL_ 1091 VCUStoredTransceiverSupplySC 1 "Error present" 0 "Error not present" ;
VAL_ 1091 VCUStoredDischargeRequestSC 1 "Error present" 0 "Error not present" ;
VAL_ 1091 VCUStoredCrashLineSC 1 "Error present" 0 "Error not present" ;
VAL_ 1091 VCUStoredABSWarningLightSC 1 "Error present" 0 "Error not present" ;
VAL_ 1091 VCUStoredImmoLightSC 1 "Error present" 0 "Error not present" ;
VAL_ 1091 VCUStoredDriveLightSC 1 "Error present" 0 "Error not present" ;
VAL_ 1091 VCUStoredAuxBattLowLightSC 1 "Error present" 0 "Error not present" ;
VAL_ 1091 VCUStoredChargeLightSC 1 "Error present" 0 "Error not present" ;
VAL_ 1091 VCUStoredTPMSLightSC 1 "Error present" 0 "Error not present" ;
VAL_ 1091 VCUStoredSpeedGaugeSC 1 "Error present" 0 "Error not present" ;
VAL_ 1091 VCUStoredEconomyLightSC 1 "Error present" 0 "Error not present" ;
VAL_ 1091 VCUStoredOnPlugLightSC 1 "Error present" 0 "Error not present" ;
VAL_ 1091 VCUStoredChimeLineSC 1 "Error present" 0 "Error not present" ;
VAL_ 1091 VCUStoredSOCGaugeSC 1 "Error present" 0 "Error not present" ;
VAL_ 1091 VCUStoredMILLightSC 1 "Error present" 0 "Error not present" ;
VAL_ 1091 VCUStoredParkLightSC 1 "Error present" 0 "Error not present" ;
VAL_ 1091 VCUStoredAirbagLightSC 1 "Error present" 0 "Error not present" ;
VAL_ 1091 VCUStoredIgnitionSpeedSC 1 "Error present" 0 "Error not present" ;
VAL_ 1091 VCUStoredRearSeatBuckle1LightSC 1 "Error present" 0 "Error not present" ;
VAL_ 1092 VCUStoredImmoLightOC 1 "Error present" 0 "Error not present" ;
VAL_ 1092 VCUStoredReverseLightOC 1 "Error present" 0 "Error not present" ;
VAL_ 1092 VCUStoredDischargeRequestOC 1 "Error present" 0 "Error not present" ;
VAL_ 1092 VCUStoredPowerLimitLightOC 1 "Error present" 0 "Error not present" ;
VAL_ 1092 VCUStoredRearSeatBuckle1LightOC 1 "Error present" 0 "Error not present" ;
VAL_ 1092 VCUStoredTPMSLightOC 1 "Error present" 0 "Error not present" ;
VAL_ 1092 VCUStoredOvertempLightOC 1 "Error present" 0 "Error not present" ;
VAL_ 1092 VCUStoredSOCGaugeOC 1 "Error present" 0 "Error not present" ;
VAL_ 1092 VCUStoredCrashLineOC 1 "Error present" 0 "Error not present" ;
VAL_ 1092 VCUStoredIndicationBarSupplyOC 1 "Error present" 0 "Error not present" ;
VAL_ 1092 VCUStoredEconomyLightOC 1 "Error present" 0 "Error not present" ;
VAL_ 1092 VCUStoredAirbagLightOC 1 "Error present" 0 "Error not present" ;
VAL_ 1092 VCUStoredEconomyGaugeOC 1 "Error present" 0 "Error not present" ;
VAL_ 1092 VCUStoredTransceiverSupplyOC 1 "Error present" 0 "Error not present" ;
VAL_ 1092 VCUStoredDriveLightOC 1 "Error present" 0 "Error not present" ;
VAL_ 1092 VCUStoredAuxBattLowLightOC 1 "Error present" 0 "Error not present" ;
VAL_ 1092 VCUStoredRearSeatBuckle2LightOC 1 "Error present" 0 "Error not present" ;
VAL_ 1092 VCUStoredIgnitionSpeedOC 1 "Error present" 0 "Error not present" ;
VAL_ 1092 VCUStoredMILLightOC 1 "Error present" 0 "Error not present" ;
VAL_ 1092 VCUStoredChimeLineOC 1 "Error present" 0 "Error not present" ;
VAL_ 1092 VCUStoredDriveEnableLightOC 1 "Error present" 0 "Error not present" ;
VAL_ 1092 VCUStoredLowSOCOC 1 "Error present" 0 "Error not present" ;
VAL_ 1092 VCUStoredElHazardLightOC 1 "Error present" 0 "Error not present" ;
VAL_ 1092 VCUStoredBrakeWarningLightOC 1 "Error present" 0 "Error not present" ;
VAL_ 1092 VCUStoredIllumOutputOC 1 "Error present" 0 "Error not present" ;
VAL_ 1092 VCUStoredABSWarningLightOC 1 "Error present" 0 "Error not present" ;
VAL_ 1092 VCUStoredTransceiverTXOC 1 "Error present" 0 "Error not present" ;
VAL_ 1092 VCUStoredBeltWarningLightOC 1 "Error present" 0 "Error not present" ;
VAL_ 1092 VCUStoredSpeedGaugeOC 1 "Error present" 0 "Error not present" ;
VAL_ 1092 VCUStoredRadioMuteOC 1 "Error present" 0 "Error not present" ;
VAL_ 1092 VCUStoredParkLightOC 1 "Error present" 0 "Error not present" ;
VAL_ 1092 VCUStoredNeutralLightOC 1 "Error present" 0 "Error not present" ;
VAL_ 1092 VCUStoredChargeLightOC 1 "Error present" 0 "Error not present" ;
VAL_ 1092 VCUStoredOnPlugLightOC 1 "Error present" 0 "Error not present" ;
VAL_ 1089 VCUPresentMILLightSC 1 "Error present" 0 "Error not present" ;
VAL_ 1089 VCUPresentImmoLightSC 1 "Error present" 0 "Error not present" ;
VAL_ 1089 VCUPresentEconomyLightSC 1 "Error present" 0 "Error not present" ;
VAL_ 1089 VCUPresentTransceiverSupplySC 1 "Error present" 0 "Error not present" ;
VAL_ 1089 VCUPresentIgnitionSpeedSC 1 "Error present" 0 "Error not present" ;
VAL_ 1089 VCUPresentChimeLineSC 1 "Error present" 0 "Error not present" ;
VAL_ 1089 VCUPresentElHazardLightSC 1 "Error present" 0 "Error not present" ;
VAL_ 1089 VCUPresentBrakeWarningLightSC 1 "Error present" 0 "Error not present" ;
VAL_ 1089 VCUPresentRadioMuteSC 1 "Error present" 0 "Error not present" ;
VAL_ 1089 VCUPresentSOCGaugeSC 1 "Error present" 0 "Error not present" ;
VAL_ 1089 VCUPresentNeutralLightSC 1 "Error present" 0 "Error not present" ;
VAL_ 1089 VCUPresentParkLightSC 1 "Error present" 0 "Error not present" ;
VAL_ 1089 VCUPresentChargeLightSC 1 "Error present" 0 "Error not present" ;
VAL_ 1089 VCUPresentEconomyGaugeSC 1 "Error present" 0 "Error not present" ;
VAL_ 1089 VCUPresentCrashLineSC 1 "Error present" 0 "Error not present" ;
VAL_ 1089 VCUPresentTransceiverTXSC 1 "Error present" 0 "Error not present" ;
VAL_ 1089 VCUPresentReverseLightSC 1 "Error present" 0 "Error not present" ;
VAL_ 1089 VCUPresentAirbagLightSC 1 "Error present" 0 "Error not present" ;
VAL_ 1089 VCUPresentIndicationBarSupplySC 1 "Error present" 0 "Error not present" ;
VAL_ 1089 VCUPresentDriveLightSC 1 "Error present" 0 "Error not present" ;
VAL_ 1089 VCUPresentRearSeatBuckle1LightSC 1 "Error present" 0 "Error not present" ;
VAL_ 1089 VCUPresentDischargeRequestSC 1 "Error present" 0 "Error not present" ;
VAL_ 1089 VCUPresentAuxBattLowLightSC 1 "Error present" 0 "Error not present" ;
VAL_ 1089 VCUPresentDriveEnableLightSC 1 "Error present" 0 "Error not present" ;
VAL_ 1089 VCUPresentLowSOCSC 1 "Error present" 0 "Error not present" ;
VAL_ 1089 VCUPresentBeltWarningLightSC 1 "Error present" 0 "Error not present" ;
VAL_ 1089 VCUPresentSpeedGaugeSC 1 "Error present" 0 "Error not present" ;
VAL_ 1089 VCUPresentABSWarningLightSC 1 "Error present" 0 "Error not present" ;
VAL_ 1089 VCUPresentOvertempLightSC 1 "Error present" 0 "Error not present" ;
VAL_ 1089 VCUPresentOnPlugLightSC 1 "Error present" 0 "Error not present" ;
VAL_ 1089 VCUPresentIllumOutputSC 1 "Error present" 0 "Error not present" ;
VAL_ 1089 VCUPresentPowerLimitLightSC 1 "Error present" 0 "Error not present" ;
VAL_ 1089 VCUPresentTPMSLightSC 1 "Error present" 0 "Error not present" ;
VAL_ 1089 VCUPresentRearSeatBuckle2LightSC 1 "Error present" 0 "Error not present" ;
VAL_ 1090 VCUPresentIndicationBarSupplyOC 1 "Error present" 0 "Error not present" ;
VAL_ 1090 VCUPresentLowSOCOC 1 "Error present" 0 "Error not present" ;
VAL_ 1090 VCUPresentOvertempLightOC 1 "Error present" 0 "Error not present" ;
VAL_ 1090 VCUPresentEconomyLightOC 1 "Error present" 0 "Error not present" ;
VAL_ 1090 VCUPresentParkLightOC 1 "Error present" 0 "Error not present" ;
VAL_ 1090 VCUPresentRadioMuteOC 1 "Error present" 0 "Error not present" ;
VAL_ 1090 VCUPresentElHazardLightOC 1 "Error present" 0 "Error not present" ;
VAL_ 1090 VCUPresentBeltWarningLightOC 1 "Error present" 0 "Error not present" ;
VAL_ 1090 VCUPresentDriveEnableLightOC 1 "Error present" 0 "Error not present" ;
VAL_ 1090 VCUPresentImmoLightOC 1 "Error present" 0 "Error not present" ;
VAL_ 1090 VCUPresentAirbagLightOC 1 "Error present" 0 "Error not present" ;
VAL_ 1090 VCUPresentSOCGaugeOC 1 "Error present" 0 "Error not present" ;
VAL_ 1090 VCUPresentSpeedGaugeOC 1 "Error present" 0 "Error not present" ;
VAL_ 1090 VCUPresentRearSeatBuckle2LightOC 1 "Error present" 0 "Error not present" ;
VAL_ 1090 VCUPresentReverseLightOC 1 "Error present" 0 "Error not present" ;
VAL_ 1090 VCUPresentIllumOutputOC 1 "Error present" 0 "Error not present" ;
VAL_ 1090 VCUPresentBrakeWarningLightOC 1 "Error present" 0 "Error not present" ;
VAL_ 1090 VCUPresentTransceiverSupplyOC 1 "Error present" 0 "Error not present" ;
VAL_ 1090 VCUPresentABSWarningLightOC 1 "Error present" 0 "Error not present" ;
VAL_ 1090 VCUPresentTransceiverTXOC 1 "Error present" 0 "Error not present" ;
VAL_ 1090 VCUPresentDriveLightOC 1 "Error present" 0 "Error not present" ;
VAL_ 1090 VCUPresentPowerLimitLightOC 1 "Error present" 0 "Error not present" ;
VAL_ 1090 VCUPresentCrashLineOC 1 "Error present" 0 "Error not present" ;
VAL_ 1090 VCUPresentIgnitionSpeedOC 1 "Error present" 0 "Error not present" ;
VAL_ 1090 VCUPresentAuxBattLowLightOC 1 "Error present" 0 "Error not present" ;
VAL_ 1090 VCUPresentChargeLightOC 1 "Error present" 0 "Error not present" ;
VAL_ 1090 VCUPresentOnPlugLightOC 1 "Error present" 0 "Error not present" ;
VAL_ 1090 VCUPresentNeutralLightOC 1 "Error present" 0 "Error not present" ;
VAL_ 1090 VCUPresentEconomyGaugeOC 1 "Error present" 0 "Error not present" ;
VAL_ 1090 VCUPresentChimeLineOC 1 "Error present" 0 "Error not present" ;
VAL_ 1090 VCUPresentRearSeatBuckle1LightOC 1 "Error present" 0 "Error not present" ;
VAL_ 1090 VCUPresentTPMSLightOC 1 "Error present" 0 "Error not present" ;
VAL_ 1090 VCUPresentDischargeRequestOC 1 "Error present" 0 "Error not present" ;
VAL_ 1090 VCUPresentMILLightOC 1 "Error present" 0 "Error not present" ;
VAL_ 929 KeyOnGearPosition 7 "Fault" 4 "Economy" 3 "Drive" 2 "Neutral" 1 "Reverse" 0 "Park" ;
VAL_ 929 VehicleState 2 "KeyOn" 1 "OnPlug" 0 "Off" ;
VAL_ 592 LEDIndication 5 "Off Plug" 4 "Slow Blink" 3 "Fast Blink" 2 "Flashing fault code" 1 "On" 0 "Off" ;
VAL_ 592 KeyStatus 3 "Deafult" 2 "Disable" 1 "Enable" 0 "Reading" ;
VAL_ 837 TPMSLearnLastResult 2 "Learn timeout" 1 "Learn success" 0 "No result" ;
VAL_ 837 TPMSTelltaleControl 2 "NHTSA MIL telltale On" 1 "NHTSA telltale On" 0 "NHTSA telltale Off" ;
VAL_ 837 TPMSWarning_RR 7 "Missing sensor" 6 "Normal" 5 "Fast deflation" 2 "Very Low (RED)" 0 "Unknown state" ;
VAL_ 837 TPMSLearnStatus 2 "Button learn in progress" 1 "Diagnostic learn in progress" 0 "No learn started" ;
VAL_ 837 TPMSWarning_LF 7 "Missing sensor" 6 "Normal" 5 "Fast deflation" 2 "Very Low (RED)" 0 "Unknown state" ;
VAL_ 837 TPMSWarning_LR 7 "Missing sensor" 6 "Normal" 5 "Fast deflation" 2 "Very Low (RED)" 0 "Unknown state" ;
VAL_ 837 TPMSWarning_RF 7 "Missing sensor" 6 "Normal" 5 "Fast deflation" 2 "Very Low (RED)" 0 "Unknown state" ;
